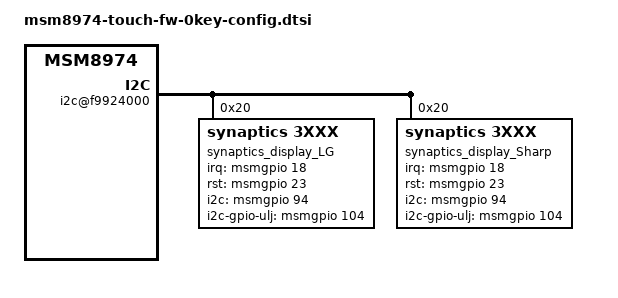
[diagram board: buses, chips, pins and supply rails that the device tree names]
/* Copyright (c) 2013, The Linux Foundation. All rights reserved.
 *
 * This program is free software; you can redistribute it and/or modify
 * it under the terms of the GNU General Public License version 2 and
 * only version 2 as published by the Free Software Foundation.
 *
 * This program is distributed in the hope that it will be useful,
 * but WITHOUT ANY WARRANTY; without even the implied warranty of
 * MERCHANTABILITY or FITNESS FOR A PARTICULAR PURPOSE.  See the
 * GNU General Public License for more details.
 */

&soc {
	i2c@f9924000 {
		synaptics_display_LG@20 {
			compatible               = "synaptics,3xxx";
			reg                      = <0x20>;
			interrupt-parent         = <&msmgpio>;
			interrupts               = <18 0x2>;
			synaptics,display-coords = <0 1080 0 1920>;
			synaptics,irq-gpio       = <&msmgpio 18 0x00>;
			synaptics,rst-gpio       = <&msmgpio 23 0x00>;
			synaptics,i2c-gpio       = <&msmgpio 94 0x00>;
			synaptics,i2c-gpio-ulj   = <&msmgpio 104 0x00>;
			synaptics,i2c_err_hlr    = <1>;
			tw_pin_mask              = <0x05>;
			hall_block_touch_time    = <1000>;
			report_type              = <1>;
			virtualkey0              = <&syn_vk>;
			virtualkey1              = <&syn_vk_1>;
			virtualkey2              = <&syn_vk_t6>;

			config_3528_0key_yfo_6 {
				default_cfg   = <1>;
				pr_number     = <1594356>;
				sensor_id     = <0x0>;
				syn,pl-coords = <0 1620 0 2880>;
				cover_setting = <0x0D 0x0D 0x1A 0x0A 0x82 0x82 0x06>;
				tp_stock_ui_check	 = <1>;
				config = [
					31 35 04 21 00 3F 03 14
					05 1D 54 06 40 0B 23 43
					5A 41 00 00 00 00 0F 1B
					01 1E 05 F5 28 1E 05 28
					10 03 12 02 CC C4 CC C4
					83 80 C4 C4 05 03 10 1E
					80 0F 0A 64 00 01 01 07
					04 04 0A C0 0A 64 26 26
					80 80 00 00 82 5F 48 64
					33 19 00 40 40 2D 50 00
					00 00 00 4C 04 6C 07 3C
					32 00 00 00 00 4C 04 6C
					07 1E 05 1E 04 0A 04 0A
					00 0A 04 04 01 01 00 00
					01 05 0A 01 00 00 06 39
					01 00 18 00 06 39 01 00
					18 33 33 CC 1C 02 19 10
					0A 64 06 64 06 C8 88 1F
					40 00 40 00 32 23 4B 50
					37 3C 0C 0C 00 00 14 14
					00 03 00 03 09 96 00 00
					14 03 06 0F 0A 00 4B FF
					00 0A C8 0A B4 64 B4 C8
					B4 C8 B4 C8 B4 C8 B4 C8
					00 05 DC 05 C8 32 C8 64
					C8 64 C8 64 C8 64 C8 64
					00 04 01 80 04 1B 00 00
					00 2C 01 FF FF BF 32 2C
					01 00 C0 80 00 10 0A 18
					00 7D 01 10 27 00 A0 00
					03 00 02 02 07 07 05 A0
					00 0C 0E 01 04 03 28 00
					10 00 00 00 07 00 02 25
					03 28 00 0F 00 02 00 07
					00 02 27 83 28 00 0F 00
					04 00 04 00 01 23 83 28
					00 0F 00 06 00 04 00 01
					24 03 28 00 0E 00 08 00
					04 00 01 25 83 28 00 0E
					00 0A 00 04 00 01 26 83
					28 00 0E 00 0C 00 09 00
					02 23 83 28 00 0D 00 0E
					00 09 00 02 24 0E 0E 0E
					0E 0E 0E 0E 0F 0F 0F 0F
					0F 0F 0F 0F 00 00 00 00
					00 00 00 03 03 03 03 03
					03 03 03 03 03 03 03 03
					03 03 03 03 03 03 03 03
					03 0E 0D 0D 0D 0D 0D 0D
					0D 0D 0D 0D 0D 0D 0D 0D
					0E 0D 0D 0D 0D 0D 0D 0D
					0D 0D 0D 0D 0D 0D 0D 0D
					0B 02 02 01 00 07 0B 0B
					03 00 05 34 00 06 00 A6
					00 14 64 05 00 00 02 02
					04 04 04 04 03 1B 28 05
					00 00 16 12 00 05 02 14
					A1 02 06 1E 08 A0 00 A0
					00 1E 03 0C 0C 14 28 04
					00 00 00 00 00 00 00 00
					00 00 00 20 00 00 00 FF
					FF FF FF FF FF FF FF 51
					51 51 51 CD 0D 04 83 10
					10 10 10 05 20 1F 1E 1D
					1C 1B 1A 18 17 16 15 14
					13 12 11 FF FF FF FF FF
					FF FF 00 01 02 03 04 05
					06 07 08 09 0A 0B 0C 0D
					33 32 31 30 2F 2E 2D 2C
					2B 2A 29 28 27 FF FF FF
					FF FF 00 10 00 10 00 10
					00 10 80 80 80 80 80 80
					80 80 80 80 80 80 80 80
					80 80 80 80 80 80 80 80
					80 80 80 80 80 80 80 80
					80 80 80 80 80 80 80 9A
					9A 80 80 80 80 80 80 80
					80 80 80 80 80 80 80 80
					00 10 00 10 00 10 00 10
					00 00 21 22 FF FF 0E 26
					35 FF
				];
			};

			config_3528_0key_pana_6 {
				default_cfg   = <1>;
				pr_number     = <1594356>;
				sensor_id     = <0x1>;
				syn,pl-coords = <0 1620 0 2880>;
				cover_setting = <0x0D 0x0D 0x1A 0x0A 0x82 0x82 0x06>;
				tp_stock_ui_check	 = <1>;
				config = [
					31 35 04 21 00 3F 03 14
					05 1D 54 06 40 0B 23 43
					5A 41 00 00 00 00 0F 1B
					01 1E 05 F5 28 1E 05 28
					10 03 12 02 CC C4 CC C4
					83 80 C4 C4 05 03 10 1E
					80 0F 0A 64 00 01 01 07
					04 04 0A C0 0A 64 26 26
					80 80 00 00 82 5F 48 64
					33 19 00 40 40 2D 50 00
					00 00 00 4C 04 6C 07 3C
					32 00 00 00 00 4C 04 6C
					07 1E 05 1E 04 0A 04 0A
					00 0A 04 04 01 01 00 00
					01 05 0A 01 00 00 06 39
					01 00 18 00 06 39 01 00
					18 33 33 CC 1C 02 19 10
					0A 64 06 64 06 C8 88 1F
					40 00 40 00 32 23 4B 50
					37 3C 0C 0C 00 00 14 14
					00 03 00 03 09 96 00 00
					14 03 06 0F 0A 00 4B FF
					00 0A C8 0A B4 64 B4 C8
					B4 C8 B4 C8 B4 C8 B4 C8
					00 05 DC 05 C8 32 C8 64
					C8 64 C8 64 C8 64 C8 64
					00 04 01 80 04 1B 00 00
					00 2C 01 FF FF BF 32 2C
					01 00 C0 80 00 10 0A 18
					00 7D 01 10 27 00 A0 00
					03 00 02 02 07 07 05 A0
					00 0C 0E 01 04 03 28 00
					10 00 00 00 07 00 02 25
					03 28 00 0F 00 02 00 07
					00 02 27 83 28 00 0F 00
					04 00 04 00 01 23 83 28
					00 0F 00 06 00 04 00 01
					24 03 28 00 0E 00 08 00
					04 00 01 25 83 28 00 0E
					00 0A 00 04 00 01 26 83
					28 00 0E 00 0C 00 09 00
					02 23 83 28 00 0D 00 0E
					00 09 00 02 24 0E 0E 0E
					0E 0E 0E 0E 0F 0F 0F 0F
					0F 0F 0F 0F 00 00 00 00
					00 00 00 03 03 03 03 03
					03 03 03 03 03 03 03 03
					03 03 03 03 03 03 03 03
					03 0E 0D 0D 0D 0D 0D 0D
					0D 0D 0D 0D 0D 0D 0D 0D
					0E 0D 0D 0D 0D 0D 0D 0D
					0D 0D 0D 0D 0D 0D 0D 0D
					0B 02 02 01 00 07 0B 0B
					03 00 05 34 00 06 00 A6
					00 14 64 05 00 00 02 02
					04 04 04 04 03 1B 28 05
					00 00 16 12 00 05 02 14
					A1 02 06 1E 08 A0 00 A0
					00 1E 03 0C 0C 14 28 04
					00 00 00 00 00 00 00 00
					00 00 00 20 00 00 00 FF
					FF FF FF FF FF FF FF 51
					51 51 51 CD 0D 04 83 10
					10 10 10 05 20 1F 1E 1D
					1C 1B 1A 18 17 16 15 14
					13 12 11 FF FF FF FF FF
					FF FF 00 01 02 03 04 05
					06 07 08 09 0A 0B 0C 0D
					33 32 31 30 2F 2E 2D 2C
					2B 2A 29 28 27 FF FF FF
					FF FF 00 10 00 10 00 10
					00 10 80 80 80 80 80 80
					80 80 80 80 80 80 80 80
					80 80 80 80 80 80 80 80
					80 80 80 80 80 80 80 80
					80 80 80 80 80 80 80 9A
					9A 80 80 80 80 80 80 80
					80 80 80 80 80 80 80 80
					00 10 00 10 00 10 00 10
					00 00 21 22 FF FF 0E 26
					35 FF
				];
			};

			config_3528_0key_yfo_5 {
				default_cfg   = <1>;
				pr_number     = <1594356>;
				sensor_id     = <0x0>;
				syn,pl-coords = <0 1620 0 2880>;
				cover_setting = <0x0D 0x0D 0x1A 0x0A 0x82 0x82 0x06>;
				config = [
					31 35 04 22 00 3F 03 14
					05 1D 54 06 40 0B 23 43
					5A 41 00 00 00 00 0F 1B
					01 1E 05 F5 28 1E 05 28
					10 03 12 02 CC C4 CC C4
					83 80 C4 C4 05 03 10 16
					80 0F 0A 64 00 01 01 07
					04 04 0A C0 0A 64 26 26
					80 80 00 00 82 5F 48 64
					2E 19 00 40 40 2D 50 00
					00 00 00 4C 04 6C 07 3C
					32 00 00 00 00 4C 04 6C
					07 1E 05 1E 04 0A 04 0A
					00 0A 04 04 01 01 00 00
					01 05 0A 01 00 00 06 39
					01 00 18 00 06 39 01 00
					18 33 33 CC 1C 02 19 10
					0A 64 06 64 06 C8 88 1F
					40 00 40 00 32 23 4B 50
					37 3C 0C 0C 00 00 14 14
					00 03 00 03 09 96 00 00
					14 03 06 0F 0A 00 4B FF
					00 0A C8 0A B4 64 B4 C8
					B4 C8 B4 C8 B4 C8 B4 C8
					00 05 DC 05 C8 32 C8 64
					C8 64 C8 64 C8 64 C8 64
					00 04 01 80 04 1B 00 00
					00 2C 01 FF FF BF 32 2C
					01 00 C0 80 00 10 0A 18
					00 7D 01 10 27 00 A0 00
					03 00 02 02 07 07 05 A0
					00 0C 0E 01 04 03 28 00
					10 00 00 00 07 00 02 25
					03 28 00 0F 00 02 00 07
					00 02 27 83 28 00 0F 00
					04 00 04 00 01 23 83 28
					00 0F 00 06 00 04 00 01
					24 03 28 00 0E 00 08 00
					04 00 01 25 83 28 00 0E
					00 0A 00 04 00 01 26 83
					28 00 0E 00 0C 00 09 00
					02 23 83 28 00 0D 00 0E
					00 09 00 02 24 0E 0E 0E
					0E 0E 0E 0E 0F 0F 0F 0F
					0F 0F 0F 0F 00 00 00 00
					00 00 00 03 03 03 03 03
					03 03 03 03 03 03 03 03
					03 03 03 03 03 03 03 03
					03 0E 0D 0D 0D 0D 0D 0D
					0D 0D 0D 0D 0D 0D 0D 0D
					0E 0D 0D 0D 0D 0D 0D 0D
					0D 0D 0D 0D 0D 0D 0D 0D
					0B 02 02 01 00 07 0B 0B
					03 00 05 34 00 06 00 A6
					00 14 64 05 00 00 02 02
					04 04 04 04 03 1B 28 05
					00 00 16 12 00 05 02 14
					A1 02 06 1E 08 A0 00 A0
					00 1E 03 0C 0C 14 28 04
					00 00 00 00 00 00 00 00
					00 00 00 20 00 00 00 FF
					FF FF FF FF FF FF FF 51
					51 51 51 CD 0D 04 83 10
					10 10 10 05 20 1F 1E 1D
					1C 1B 1A 18 17 16 15 14
					13 12 11 FF FF FF FF FF
					FF FF 00 01 02 03 04 05
					06 07 08 09 0A 0B 0C 0D
					33 32 31 30 2F 2E 2D 2C
					2B 2A 29 28 27 FF FF FF
					FF FF 00 10 00 10 00 10
					00 10 80 80 80 80 80 80
					80 80 80 80 80 80 80 80
					80 80 80 80 80 80 80 80
					80 80 80 80 80 80 80 80
					80 80 80 80 80 80 80 9A
					9A 80 80 80 80 80 80 80
					80 80 80 80 80 80 80 80
					00 10 00 10 00 10 00 10
					00 00 21 22 FF FF 0E 26
					35 FF
				];
			};

			config_3528_0key_pana_5 {
				default_cfg   = <1>;
				pr_number     = <1594356>;
				sensor_id     = <0x1>;
				syn,pl-coords = <0 1620 0 2880>;
				cover_setting = <0x0D 0x0D 0x1A 0x0A 0x82 0x82 0x06>;
				config = [
					31 35 04 22 00 3F 03 14
					05 1D 54 06 40 0B 23 43
					5A 41 00 00 00 00 0F 1B
					01 1E 05 F5 28 1E 05 28
					10 03 12 02 CC C4 CC C4
					83 80 C4 C4 05 03 10 16
					80 0F 0A 64 00 01 01 07
					04 04 0A C0 0A 64 26 26
					80 80 00 00 82 5F 48 64
					2E 19 00 40 40 2D 50 00
					00 00 00 4C 04 6C 07 3C
					32 00 00 00 00 4C 04 6C
					07 1E 05 1E 04 0A 04 0A
					00 0A 04 04 01 01 00 00
					01 05 0A 01 00 00 06 39
					01 00 18 00 06 39 01 00
					18 33 33 CC 1C 02 19 10
					0A 64 06 64 06 C8 88 1F
					40 00 40 00 32 23 4B 50
					37 3C 0C 0C 00 00 14 14
					00 03 00 03 09 96 00 00
					14 03 06 0F 0A 00 4B FF
					00 0A C8 0A B4 64 B4 C8
					B4 C8 B4 C8 B4 C8 B4 C8
					00 05 DC 05 C8 32 C8 64
					C8 64 C8 64 C8 64 C8 64
					00 04 01 80 04 1B 00 00
					00 2C 01 FF FF BF 32 2C
					01 00 C0 80 00 10 0A 18
					00 7D 01 10 27 00 A0 00
					03 00 02 02 07 07 05 A0
					00 0C 0E 01 04 03 28 00
					10 00 00 00 07 00 02 25
					03 28 00 0F 00 02 00 07
					00 02 27 83 28 00 0F 00
					04 00 04 00 01 23 83 28
					00 0F 00 06 00 04 00 01
					24 03 28 00 0E 00 08 00
					04 00 01 25 83 28 00 0E
					00 0A 00 04 00 01 26 83
					28 00 0E 00 0C 00 09 00
					02 23 83 28 00 0D 00 0E
					00 09 00 02 24 0E 0E 0E
					0E 0E 0E 0E 0F 0F 0F 0F
					0F 0F 0F 0F 00 00 00 00
					00 00 00 03 03 03 03 03
					03 03 03 03 03 03 03 03
					03 03 03 03 03 03 03 03
					03 0E 0D 0D 0D 0D 0D 0D
					0D 0D 0D 0D 0D 0D 0D 0D
					0E 0D 0D 0D 0D 0D 0D 0D
					0D 0D 0D 0D 0D 0D 0D 0D
					0B 02 02 01 00 07 0B 0B
					03 00 05 34 00 06 00 A6
					00 14 64 05 00 00 02 02
					04 04 04 04 03 1B 28 05
					00 00 16 12 00 05 02 14
					A1 02 06 1E 08 A0 00 A0
					00 1E 03 0C 0C 14 28 04
					00 00 00 00 00 00 00 00
					00 00 00 20 00 00 00 FF
					FF FF FF FF FF FF FF 51
					51 51 51 CD 0D 04 83 10
					10 10 10 05 20 1F 1E 1D
					1C 1B 1A 18 17 16 15 14
					13 12 11 FF FF FF FF FF
					FF FF 00 01 02 03 04 05
					06 07 08 09 0A 0B 0C 0D
					33 32 31 30 2F 2E 2D 2C
					2B 2A 29 28 27 FF FF FF
					FF FF 00 10 00 10 00 10
					00 10 80 80 80 80 80 80
					80 80 80 80 80 80 80 80
					80 80 80 80 80 80 80 80
					80 80 80 80 80 80 80 80
					80 80 80 80 80 80 80 9A
					9A 80 80 80 80 80 80 80
					80 80 80 80 80 80 80 80
					00 10 00 10 00 10 00 10
					00 00 21 22 FF FF 0E 26
					35 FF
				];
			};

			config_3528_0key_yfo_4 {
				default_cfg   = <1>;
				pr_number     = <1589401>;
				sensor_id     = <0x0>;
				syn,pl-coords = <0 1620 0 2880>;
				cover_setting = <0x0D 0x0D 0x1A 0x0A 0x82 0x82 0x06>;
				config = [
					31 35 04 14 00 3F 03 1E
					05 1D 54 06 40 0B 23 43
					5A 41 00 00 00 00 0F 1B
					01 1E 05 F5 28 1E 05 28
					10 03 12 02 CC C4 CC C4
					83 80 C4 C4 05 03 10 16
					80 0F 0A 64 00 01 01 07
					04 04 0A C0 0A 64 26 26
					80 80 00 00 82 5F 48 64
					2E 23 00 40 40 2D 50 00
					00 00 00 4C 04 6C 07 3C
					32 00 00 00 00 4C 04 6C
					07 1E 05 1E 04 0A 04 0A
					00 0A 04 04 01 01 00 00
					01 05 0A 01 00 00 06 39
					01 00 18 00 06 39 01 00
					18 33 33 CC 1C 02 19 10
					0A 64 06 64 06 C8 88 1F
					40 00 40 00 32 23 4B 50
					37 3C 0C 0C 00 00 14 14
					00 03 00 03 09 96 00 00
					14 03 06 0F 0A 00 4B FF
					00 0A C8 0A B4 64 B4 C8
					B4 C8 B4 C8 B4 C8 B4 C8
					00 05 DC 05 C8 32 C8 64
					C8 64 C8 64 C8 64 C8 64
					00 04 01 80 04 1B 00 00
					00 82 00 FF FF BF 32 2C
					01 00 C0 80 00 10 0A 18
					00 7D 01 04 00 00 A0 00
					03 00 02 02 07 07 05 A0
					00 0C 0E 02 04 00 1A 00
					10 00 00 00 07 00 02 25
					00 19 00 0F 00 02 00 07
					00 02 27 80 18 00 0F 00
					05 00 04 00 01 24 80 17
					00 0E 00 08 00 04 00 01
					25 00 16 00 0E 00 0B 00
					09 00 02 22 80 16 00 0D
					00 0E 00 09 00 02 24 80
					15 00 0D 00 11 00 09 00
					02 25 80 14 00 0C 00 15
					00 05 00 01 23 0E 0E 0E
					0E 0E 0E 0E 0F 0F 0F 0F
					0F 0F 0F 0F 00 00 00 00
					00 00 00 03 03 03 03 03
					03 03 03 03 03 03 03 03
					03 03 03 03 03 03 03 03
					03 0E 0D 0D 0D 0D 0D 0D
					0D 0D 0D 0D 0D 0D 0D 0D
					0E 0D 0D 0D 0D 0D 0D 0D
					0D 0D 0D 0D 0D 0D 0D 0D
					0B 02 02 01 00 07 0B 0B
					03 00 05 34 00 06 00 A6
					00 14 64 05 00 00 02 02
					04 04 04 04 03 1B 28 05
					00 00 14 12 00 05 02 16
					A1 02 06 1E 08 A0 00 A0
					00 1E 03 0C 0C 14 28 04
					00 00 00 00 00 00 00 00
					00 00 00 20 00 00 00 FF
					FF FF FF FF FF FF FF 51
					51 51 51 CD 0D 04 83 10
					10 10 10 05 20 1F 1E 1D
					1C 1B 1A 18 17 16 15 14
					13 12 11 FF FF FF FF FF
					FF FF 00 01 02 03 04 05
					06 07 08 09 0A 0B 0C 0D
					33 32 31 30 2F 2E 2D 2C
					2B 2A 29 28 27 FF FF FF
					FF FF 00 10 00 10 00 10
					00 10 80 80 80 80 80 80
					80 80 80 80 80 80 80 80
					80 80 80 80 80 80 80 80
					80 80 80 80 80 80 80 80
					80 80 80 80 80 80 80 80
					80 80 80 80 80 80 80 80
					80 80 80 80 80 80 80 80
					00 10 00 10 00 10 00 10
					00 00 21 22 FF FF 0E 26
					35 FF
				];
			};

			config_3528_0key_pana_4 {
				default_cfg   = <1>;
				pr_number     = <1589401>;
				sensor_id     = <0x1>;
				syn,pl-coords = <0 1620 0 2880>;
				cover_setting = <0x0D 0x0D 0x1A 0x0A 0x82 0x82 0x06>;
				config = [
					31 35 04 14 00 3F 03 1E
					05 1D 54 06 40 0B 23 43
					5A 41 00 00 00 00 0F 1B
					01 1E 05 F5 28 1E 05 28
					10 03 12 02 CC C4 CC C4
					83 80 C4 C4 05 03 10 16
					80 0F 0A 64 00 01 01 07
					04 04 0A C0 0A 64 26 26
					80 80 00 00 82 5F 48 64
					2E 23 00 40 40 2D 50 00
					00 00 00 4C 04 6C 07 3C
					32 00 00 00 00 4C 04 6C
					07 1E 05 1E 04 0A 04 0A
					00 0A 04 04 01 01 00 00
					01 05 0A 01 00 00 06 39
					01 00 18 00 06 39 01 00
					18 33 33 CC 1C 02 19 10
					0A 64 06 64 06 C8 88 1F
					40 00 40 00 32 23 4B 50
					37 3C 0C 0C 00 00 14 14
					00 03 00 03 09 96 00 00
					14 03 06 0F 0A 00 4B FF
					00 0A C8 0A B4 64 B4 C8
					B4 C8 B4 C8 B4 C8 B4 C8
					00 05 DC 05 C8 32 C8 64
					C8 64 C8 64 C8 64 C8 64
					00 04 01 80 04 1B 00 00
					00 82 00 FF FF BF 32 2C
					01 00 C0 80 00 10 0A 18
					00 7D 01 04 00 00 A0 00
					03 00 02 02 07 07 05 A0
					00 0C 0E 02 04 00 1A 00
					10 00 00 00 07 00 02 25
					00 19 00 0F 00 02 00 07
					00 02 27 80 18 00 0F 00
					05 00 04 00 01 24 80 17
					00 0E 00 08 00 04 00 01
					25 00 16 00 0E 00 0B 00
					09 00 02 22 80 16 00 0D
					00 0E 00 09 00 02 24 80
					15 00 0D 00 11 00 09 00
					02 25 80 14 00 0C 00 15
					00 05 00 01 23 0E 0E 0E
					0E 0E 0E 0E 0F 0F 0F 0F
					0F 0F 0F 0F 00 00 00 00
					00 00 00 03 03 03 03 03
					03 03 03 03 03 03 03 03
					03 03 03 03 03 03 03 03
					03 0E 0D 0D 0D 0D 0D 0D
					0D 0D 0D 0D 0D 0D 0D 0D
					0E 0D 0D 0D 0D 0D 0D 0D
					0D 0D 0D 0D 0D 0D 0D 0D
					0B 02 02 01 00 07 0B 0B
					03 00 05 34 00 06 00 A6
					00 14 64 05 00 00 02 02
					04 04 04 04 03 1B 28 05
					00 00 14 12 00 05 02 16
					A1 02 06 1E 08 A0 00 A0
					00 1E 03 0C 0C 14 28 04
					00 00 00 00 00 00 00 00
					00 00 00 20 00 00 00 FF
					FF FF FF FF FF FF FF 51
					51 51 51 CD 0D 04 83 10
					10 10 10 05 20 1F 1E 1D
					1C 1B 1A 18 17 16 15 14
					13 12 11 FF FF FF FF FF
					FF FF 00 01 02 03 04 05
					06 07 08 09 0A 0B 0C 0D
					33 32 31 30 2F 2E 2D 2C
					2B 2A 29 28 27 FF FF FF
					FF FF 00 10 00 10 00 10
					00 10 80 80 80 80 80 80
					80 80 80 80 80 80 80 80
					80 80 80 80 80 80 80 80
					80 80 80 80 80 80 80 80
					80 80 80 80 80 80 80 80
					80 80 80 80 80 80 80 80
					80 80 80 80 80 80 80 80
					00 10 00 10 00 10 00 10
					00 00 21 22 FF FF 0E 26
					35 FF
				];
			};

			config_3528_0key_yfo_3 {
				default_cfg   = <1>;
				pr_number     = <1584735>;
				sensor_id     = <0x0>;
				syn,pl-coords = <0 1620 0 2880>;
				config = [
					31 35 04 11 00 3F 03 1E
					05 1D 54 06 40 0B 23 43
					5A 41 00 00 00 00 0F 1B
					01 1E 05 F5 28 1E 05 28
					10 03 12 02 CC C4 CC C4
					83 80 C4 C4 05 03 1C 1E
					80 0F 0A 64 00 01 01 07
					04 04 0A C0 0A 64 26 26
					80 80 00 00 C0 53 5B 80
					2E 1A 00 40 40 2D 50 00
					00 00 00 4C 04 6C 07 3C
					32 00 00 00 00 4C 04 6C
					07 1E 05 1E 04 0A 04 0A
					00 0A 04 04 01 01 00 00
					01 05 0A 0A 00 00 06 39
					01 00 18 00 06 39 01 00
					18 33 33 CC 1C 02 19 10
					0A 64 06 64 06 C8 88 1F
					40 00 40 00 32 23 4B 50
					37 3C 0C 0C 00 00 14 14
					00 03 00 03 09 96 00 00
					14 03 06 0F 0A 00 4B FF
					FF 19 FF 19 FF 19 FF 19
					FF 19 FF 19 FF 19 FF 19
					FF 13 FF 13 FF 13 FF 13
					FF 13 FF 13 FF 13 FF 13
					00 04 01 80 04 1B 00 00
					00 64 00 F4 01 BF 28 F4
					01 00 C0 80 00 10 0A 18
					00 7D 01 03 00 00 64 00
					03 00 06 06 07 07 00 64
					00 0C 0E 01 04 00 1A 00
					10 00 00 00 07 00 02 25
					00 19 00 0F 00 02 00 07
					00 02 27 80 18 00 0F 00
					05 00 04 00 01 24 80 17
					00 0E 00 08 00 04 00 01
					25 80 16 00 0E 00 0B 00
					09 00 02 22 00 16 00 0D
					00 0E 00 09 00 02 24 80
					15 00 0D 00 11 00 09 00
					02 25 80 14 00 0C 00 15
					00 05 00 01 23 00 00 00
					00 00 00 00 00 00 00 00
					00 00 00 00 00 00 00 00
					00 00 00 03 03 03 03 03
					03 03 03 03 03 03 03 03
					03 03 03 03 03 03 03 03
					03 0E 0D 0D 0D 0D 0D 0D
					0D 0D 0D 0D 0D 0D 0D 0D
					0E 0D 0D 0D 0D 0D 0D 0D
					0D 0D 0D 0D 0D 0D 0D 0D
					0B 02 02 01 00 07 0B 0B
					03 00 05 34 00 06 00 A6
					00 14 64 05 00 00 02 02
					04 04 04 04 03 1B 28 05
					00 00 16 12 00 05 02 16
					A1 02 06 1E 08 A0 00 A0
					00 1E 03 0C 0C 14 28 04
					00 00 00 00 00 00 00 00
					00 00 00 20 00 00 00 FF
					FF FF FF FF FF FF FF 51
					51 51 51 CD 0D 04 83 10
					10 10 10 05 20 1F 1E 1D
					1C 1B 1A 18 17 16 15 14
					13 12 11 FF FF FF FF FF
					FF FF 00 01 02 03 04 05
					06 07 08 09 0A 0B 0C 0D
					33 32 31 30 2F 2E 2D 2C
					2B 2A 29 28 27 FF FF FF
					FF FF 00 10 00 10 00 10
					00 10 80 80 80 80 80 80
					80 80 80 80 80 80 80 80
					80 80 80 80 80 80 80 80
					80 80 80 80 80 80 80 80
					80 80 80 80 80 80 80 80
					80 80 80 80 80 80 80 80
					80 80 80 80 80 80 80 80
					00 10 00 10 00 10 00 10
					00 00 21 22 FF FF 0E 26
					35 FF
				];
			};

			config_3528_0key_pana_3 {
				default_cfg   = <1>;
				pr_number     = <1584735>;
				sensor_id     = <0x1>;
				syn,pl-coords = <0 1620 0 2880>;
				config = [
					31 35 04 11 00 3F 03 1E
					05 1D 54 06 40 0B 23 43
					5A 41 00 00 00 00 0F 1B
					01 1E 05 F5 28 1E 05 28
					10 03 12 02 CC C4 CC C4
					83 80 C4 C4 05 03 1C 1E
					80 0F 0A 64 00 01 01 07
					04 04 0A C0 0A 64 26 26
					80 80 00 00 C0 53 5B 80
					2E 1A 00 40 40 2D 50 00
					00 00 00 4C 04 6C 07 3C
					32 00 00 00 00 4C 04 6C
					07 1E 05 1E 04 0A 04 0A
					00 0A 04 04 01 01 00 00
					01 05 0A 0A 00 00 06 39
					01 00 18 00 06 39 01 00
					18 33 33 CC 1C 02 19 10
					0A 64 06 64 06 C8 88 1F
					40 00 40 00 32 23 4B 50
					37 3C 0C 0C 00 00 14 14
					00 03 00 03 09 96 00 00
					14 03 06 0F 0A 00 4B FF
					FF 19 FF 19 FF 19 FF 19
					FF 19 FF 19 FF 19 FF 19
					FF 13 FF 13 FF 13 FF 13
					FF 13 FF 13 FF 13 FF 13
					00 04 01 80 04 1B 00 00
					00 64 00 F4 01 BF 28 F4
					01 00 C0 80 00 10 0A 18
					00 7D 01 03 00 00 64 00
					03 00 06 06 07 07 00 64
					00 0C 0E 01 04 00 1A 00
					10 00 00 00 07 00 02 25
					00 19 00 0F 00 02 00 07
					00 02 27 80 18 00 0F 00
					05 00 04 00 01 24 80 17
					00 0E 00 08 00 04 00 01
					25 80 16 00 0E 00 0B 00
					09 00 02 22 00 16 00 0D
					00 0E 00 09 00 02 24 80
					15 00 0D 00 11 00 09 00
					02 25 80 14 00 0C 00 15
					00 05 00 01 23 00 00 00
					00 00 00 00 00 00 00 00
					00 00 00 00 00 00 00 00
					00 00 00 03 03 03 03 03
					03 03 03 03 03 03 03 03
					03 03 03 03 03 03 03 03
					03 0E 0D 0D 0D 0D 0D 0D
					0D 0D 0D 0D 0D 0D 0D 0D
					0E 0D 0D 0D 0D 0D 0D 0D
					0D 0D 0D 0D 0D 0D 0D 0D
					0B 02 02 01 00 07 0B 0B
					03 00 05 34 00 06 00 A6
					00 14 64 05 00 00 02 02
					04 04 04 04 03 1B 28 05
					00 00 16 12 00 05 02 16
					A1 02 06 1E 08 A0 00 A0
					00 1E 03 0C 0C 14 28 04
					00 00 00 00 00 00 00 00
					00 00 00 20 00 00 00 FF
					FF FF FF FF FF FF FF 51
					51 51 51 CD 0D 04 83 10
					10 10 10 05 20 1F 1E 1D
					1C 1B 1A 18 17 16 15 14
					13 12 11 FF FF FF FF FF
					FF FF 00 01 02 03 04 05
					06 07 08 09 0A 0B 0C 0D
					33 32 31 30 2F 2E 2D 2C
					2B 2A 29 28 27 FF FF FF
					FF FF 00 10 00 10 00 10
					00 10 80 80 80 80 80 80
					80 80 80 80 80 80 80 80
					80 80 80 80 80 80 80 80
					80 80 80 80 80 80 80 80
					80 80 80 80 80 80 80 80
					80 80 80 80 80 80 80 80
					80 80 80 80 80 80 80 80
					00 10 00 10 00 10 00 10
					00 00 21 22 FF FF 0E 26
					35 FF
				];
			};

			config_3528_0key_yfo_2 {
				default_cfg   = <1>;
				pr_number     = <1582731>;
				sensor_id     = <0x0>;
				syn,pl-coords = <0 1620 0 2880>;
				config = [
					31 35 04 09 00 3F 03 1E
					05 1D 54 06 40 0B 23 43
					5A 41 00 00 00 00 0F 1B
					01 1E 05 F5 28 1E 05 28
					10 03 12 02 CC C4 CC C4
					83 80 C4 C4 05 03 0C 12
					80 0F 0A 64 00 01 01 07
					04 04 0A C0 0A 64 26 26
					80 80 00 00 C0 53 5B 80
					26 0E 00 40 40 2D 50 00
					00 00 00 4C 04 6C 07 3C
					32 00 00 00 00 4C 04 6C
					07 1E 05 1E 04 0A 04 0A
					00 0A 04 04 01 01 00 00
					15 05 0A 0A 00 00 06 39
					01 00 18 00 06 39 01 00
					18 33 33 CC 1C 02 19 10
					0A 64 06 64 06 C8 88 1F
					40 00 40 00 32 23 4B 50
					37 3C 0C 0C 00 00 14 14
					00 03 00 03 09 96 00 00
					14 03 06 0F 0A 00 4B FF
					00 19 80 19 C0 80 C0 FF
					00 19 00 19 00 19 00 19
					00 13 C0 13 FF 80 FF FF
					FF FF FF FF FF FF FF FF
					00 04 01 80 04 1B 00 00
					00 64 00 F4 01 BF 28 F4
					01 00 C0 80 00 10 0A 18
					00 7D 01 03 00 00 96 00
					03 00 06 06 07 07 00 96
					00 0C 0E 01 04 00 1A 00
					10 00 00 00 07 00 02 25
					00 19 00 0F 00 02 00 07
					00 02 27 80 18 00 0F 00
					05 00 04 00 01 24 80 17
					00 0E 00 08 00 04 00 01
					25 00 16 00 0E 00 0B 00
					09 00 02 22 80 16 00 0D
					00 0E 00 09 00 02 24 80
					15 00 0D 00 11 00 09 00
					02 25 80 14 00 0C 00 15
					00 05 00 01 23 00 00 00
					00 00 00 00 00 00 00 00
					00 00 00 00 00 00 00 00
					00 00 00 03 03 03 03 03
					03 03 03 03 03 03 03 03
					03 03 03 03 03 03 03 03
					03 0E 0D 0D 0D 0D 0D 0D
					0D 0D 0D 0D 0D 0D 0D 0D
					0E 0D 0D 0D 0D 0D 0D 0D
					0D 0D 0D 0D 0D 0D 0D 0D
					0B 02 02 01 00 07 0B 0B
					03 00 05 34 00 06 00 A6
					00 14 64 05 00 00 02 02
					04 04 04 04 03 1B 28 05
					00 00 16 12 00 05 02 14
					A1 02 06 1E 08 A0 00 A0
					00 1E 03 0C 0C 14 28 04
					00 00 00 00 00 00 00 00
					00 00 00 20 00 00 00 FF
					FF FF FF FF FF FF FF 51
					51 51 51 CD 0D 04 83 10
					10 10 10 05 20 1F 1E 1D
					1C 1B 1A 18 17 16 15 14
					13 12 11 FF FF FF FF FF
					FF FF 00 01 02 03 04 05
					06 07 08 09 0A 0B 0C 0D
					33 32 31 30 2F 2E 2D 2C
					2B 2A 29 28 27 FF FF FF
					FF FF 00 10 00 10 00 10
					00 10 80 80 80 80 80 80
					80 80 80 80 80 80 80 80
					80 80 80 80 80 80 80 80
					80 80 80 80 80 80 80 80
					80 80 80 80 80 80 80 80
					80 80 80 80 80 80 80 80
					80 80 80 80 80 80 80 80
					00 10 00 10 00 10 00 10
					00 00 21 22 FF FF 0E 26
					35 FF
				];
			};

			config_3528_0key_pana_2 {
				default_cfg   = <1>;
				pr_number     = <1582731>;
				sensor_id     = <0x1>;
				syn,pl-coords = <0 1620 0 2880>;
				config = [
					31 35 04 09 00 3F 03 1E
					05 1D 54 06 40 0B 23 43
					5A 41 00 00 00 00 0F 1B
					01 1E 05 F5 28 1E 05 28
					10 03 12 02 CC C4 CC C4
					83 80 C4 C4 05 03 0C 12
					80 0F 0A 64 00 01 01 07
					04 04 0A C0 0A 64 26 26
					80 80 00 00 C0 53 5B 80
					26 0E 00 40 40 2D 50 00
					00 00 00 4C 04 6C 07 3C
					32 00 00 00 00 4C 04 6C
					07 1E 05 1E 04 0A 04 0A
					00 0A 04 04 01 01 00 00
					15 05 0A 0A 00 00 06 39
					01 00 18 00 06 39 01 00
					18 33 33 CC 1C 02 19 10
					0A 64 06 64 06 C8 88 1F
					40 00 40 00 32 23 4B 50
					37 3C 0C 0C 00 00 14 14
					00 03 00 03 09 96 00 00
					14 03 06 0F 0A 00 4B FF
					00 19 80 19 C0 80 C0 FF
					00 19 00 19 00 19 00 19
					00 13 C0 13 FF 80 FF FF
					FF FF FF FF FF FF FF FF
					00 04 01 80 04 1B 00 00
					00 64 00 F4 01 BF 28 F4
					01 00 C0 80 00 10 0A 18
					00 7D 01 03 00 00 96 00
					03 00 06 06 07 07 00 96
					00 0C 0E 01 04 00 1A 00
					10 00 00 00 07 00 02 25
					00 19 00 0F 00 02 00 07
					00 02 27 80 18 00 0F 00
					05 00 04 00 01 24 80 17
					00 0E 00 08 00 04 00 01
					25 00 16 00 0E 00 0B 00
					09 00 02 22 80 16 00 0D
					00 0E 00 09 00 02 24 80
					15 00 0D 00 11 00 09 00
					02 25 80 14 00 0C 00 15
					00 05 00 01 23 00 00 00
					00 00 00 00 00 00 00 00
					00 00 00 00 00 00 00 00
					00 00 00 03 03 03 03 03
					03 03 03 03 03 03 03 03
					03 03 03 03 03 03 03 03
					03 0E 0D 0D 0D 0D 0D 0D
					0D 0D 0D 0D 0D 0D 0D 0D
					0E 0D 0D 0D 0D 0D 0D 0D
					0D 0D 0D 0D 0D 0D 0D 0D
					0B 02 02 01 00 07 0B 0B
					03 00 05 34 00 06 00 A6
					00 14 64 05 00 00 02 02
					04 04 04 04 03 1B 28 05
					00 00 16 12 00 05 02 14
					A1 02 06 1E 08 A0 00 A0
					00 1E 03 0C 0C 14 28 04
					00 00 00 00 00 00 00 00
					00 00 00 20 00 00 00 FF
					FF FF FF FF FF FF FF 51
					51 51 51 CD 0D 04 83 10
					10 10 10 05 20 1F 1E 1D
					1C 1B 1A 18 17 16 15 14
					13 12 11 FF FF FF FF FF
					FF FF 00 01 02 03 04 05
					06 07 08 09 0A 0B 0C 0D
					33 32 31 30 2F 2E 2D 2C
					2B 2A 29 28 27 FF FF FF
					FF FF 00 10 00 10 00 10
					00 10 80 80 80 80 80 80
					80 80 80 80 80 80 80 80
					80 80 80 80 80 80 80 80
					80 80 80 80 80 80 80 80
					80 80 80 80 80 80 80 80
					80 80 80 80 80 80 80 80
					80 80 80 80 80 80 80 80
					00 10 00 10 00 10 00 10
					00 00 21 22 FF FF 0E 26
					35 FF
				];
			};

			config_3528_0key_yfo_1 {
				default_cfg   = <1>;
				pr_number     = <1564828>;
				sensor_id     = <0x0>;
				syn,pl-coords = <0 1620 0 2880>;
				config = [
					31 35 04 03 00 3F 03 05
					14 1D 54 06 40 0B 23 43
					5A 41 00 00 00 00 0F 1B
					01 1E 05 CD 2C A9 01 50
					16 02 1B 01 17 C3 59 E1
					83 80 C4 C4 05 03 0C 12
					80 0F 0A 64 00 01 01 07
					04 04 0A C0 0A 64 26 26
					80 80 00 00 4D 3B 01 40
					40 2D 50 00 00 00 00 4C
					04 6C 07 3C 32 00 00 00
					00 4C 04 6C 07 1E 05 1E
					04 0A 04 0A 00 0A 04 04
					01 01 00 00 01 15 0A 00
					00 00 04 39 01 00 18 F4
					01 39 01 00 18 33 33 CC
					1C 02 19 10 0A 30 06 30
					06 0A 88 1F 40 00 40 00
					32 23 4B 50 37 3C 0C 0C
					00 00 14 14 00 03 00 03
					09 96 00 00 14 03 06 0F
					0A 00 4B FF 00 04 01 80
					04 1B 00 00 00 C8 00 F4
					01 BF 32 F4 01 00 C0 80
					00 10 0A 18 00 7D 01 04
					00 00 96 00 03 00 06 06
					07 07 00 C8 00 0D 0D 01
					04 02 25 00 10 00 00 00
					07 00 02 24 02 23 00 10
					00 03 00 07 00 02 26 02
					22 00 0F 00 06 00 04 00
					01 23 81 20 00 0E 00 09
					00 04 00 01 24 01 1E 00
					0E 00 0E 00 09 00 02 23
					81 1C 00 0D 00 13 00 09
					00 02 25 80 1B 00 0C 00
					18 00 05 00 01 23 00 19
					00 0B 00 1F 00 05 00 01
					26 00 00 00 00 00 00 00
					00 00 00 00 00 00 00 00
					09 0F 00 00 00 00 00 03
					03 03 03 03 03 03 03 03
					03 03 03 03 03 03 03 03
					03 03 03 03 03 0E 0D 0D
					0D 0D 0D 0D 0D 0D 0D 0D
					0D 0D 0D 0D 0E 0D 0D 0D
					0D 0D 0D 0D 0D 0D 0D 0D
					0D 0D 0D 0D 0B 02 02 01
					00 06 0B 0B 03 00 05 32
					00 06 00 A6 00 14 64 05
					02 02 02 02 04 04 04 04
					00 2F 05 05 00 3F 38 00
					05 02 18 21 02 06 1E 08
					A0 00 A0 00 1E 03 0C 0C
					0A 0A 04 00 00 00 00 00
					00 00 00 00 00 00 00 00
					00 FF FF FF FF FF FF FF
					FF BF 97 51 51 CD 0D 04
					83 10 10 10 10 05 20 1F
					1E 1D 1C 1B 1A 18 17 16
					15 14 13 12 11 FF FF FF
					FF FF FF FF 00 01 02 03
					04 05 06 07 08 09 0A 0B
					0C 0D 33 32 31 30 2F 2E
					2D 2C 2B 2A 29 28 27 FF
					FF FF FF FF 00 10 00 10
					00 10 00 10 80 80 80 80
					80 80 80 80 80 80 80 80
					80 80 80 80 80 80 80 80
					80 80 80 80 80 80 80 80
					80 80 80 80 80 80 80 80
					80 80 80 80 80 80 80 80
					80 80 80 80 80 80 80 80
					80 80 00 10 00 10 00 10
					00 10 00 00 21 22 FF FF
					0E 26 35 FF
				];
			};

			config_3528_0key_pana_1 {
				default_cfg   = <1>;
				pr_number     = <1564828>;
				sensor_id     = <0x1>;
				syn,pl-coords = <0 1620 0 2880>;
				config = [
					31 35 04 03 00 3F 03 05
					14 1D 54 06 40 0B 23 43
					5A 41 00 00 00 00 0F 1B
					01 1E 05 CD 2C A9 01 50
					16 02 1B 01 17 C3 59 E1
					83 80 C4 C4 05 03 0C 12
					80 0F 0A 64 00 01 01 07
					04 04 0A C0 0A 64 26 26
					80 80 00 00 4D 3B 01 40
					40 2D 50 00 00 00 00 4C
					04 6C 07 3C 32 00 00 00
					00 4C 04 6C 07 1E 05 1E
					04 0A 04 0A 00 0A 04 04
					01 01 00 00 01 15 0A 00
					00 00 04 39 01 00 18 F4
					01 39 01 00 18 33 33 CC
					1C 02 19 10 0A 30 06 30
					06 0A 88 1F 40 00 40 00
					32 23 4B 50 37 3C 0C 0C
					00 00 14 14 00 03 00 03
					09 96 00 00 14 03 06 0F
					0A 00 4B FF 00 04 01 80
					04 1B 00 00 00 C8 00 F4
					01 BF 32 F4 01 00 C0 80
					00 10 0A 18 00 7D 01 04
					00 00 96 00 03 00 06 06
					07 07 00 C8 00 0D 0D 01
					04 02 25 00 10 00 00 00
					07 00 02 24 02 23 00 10
					00 03 00 07 00 02 26 02
					22 00 0F 00 06 00 04 00
					01 23 81 20 00 0E 00 09
					00 04 00 01 24 01 1E 00
					0E 00 0E 00 09 00 02 23
					81 1C 00 0D 00 13 00 09
					00 02 25 80 1B 00 0C 00
					18 00 05 00 01 23 00 19
					00 0B 00 1F 00 05 00 01
					26 00 00 00 00 00 00 00
					00 00 00 00 00 00 00 00
					09 0F 00 00 00 00 00 03
					03 03 03 03 03 03 03 03
					03 03 03 03 03 03 03 03
					03 03 03 03 03 0E 0D 0D
					0D 0D 0D 0D 0D 0D 0D 0D
					0D 0D 0D 0D 0E 0D 0D 0D
					0D 0D 0D 0D 0D 0D 0D 0D
					0D 0D 0D 0D 0B 02 02 01
					00 06 0B 0B 03 00 05 32
					00 06 00 A6 00 14 64 05
					02 02 02 02 04 04 04 04
					00 2F 05 05 00 3F 38 00
					05 02 18 21 02 06 1E 08
					A0 00 A0 00 1E 03 0C 0C
					0A 0A 04 00 00 00 00 00
					00 00 00 00 00 00 00 00
					00 FF FF FF FF FF FF FF
					FF BF 97 51 51 CD 0D 04
					83 10 10 10 10 05 20 1F
					1E 1D 1C 1B 1A 18 17 16
					15 14 13 12 11 FF FF FF
					FF FF FF FF 00 01 02 03
					04 05 06 07 08 09 0A 0B
					0C 0D 33 32 31 30 2F 2E
					2D 2C 2B 2A 29 28 27 FF
					FF FF FF FF 00 10 00 10
					00 10 00 10 80 80 80 80
					80 80 80 80 80 80 80 80
					80 80 80 80 80 80 80 80
					80 80 80 80 80 80 80 80
					80 80 80 80 80 80 80 80
					80 80 80 80 80 80 80 80
					80 80 80 80 80 80 80 80
					80 80 00 10 00 10 00 10
					00 10 00 00 21 22 FF FF
					0E 26 35 FF
				];
			};

			config_0key_3 {
				default_cfg   = <1>;
				pr_number     = <1558162>;
				sensor_id     = <0x0>;
				syn,pl-coords = <0 1620 0 2880>;
				config = [
					31 35 02 01 00 3F 03 1E
					05 0E 54 06 40 0B 23 43
					5A 41 00 00 00 00 0F 1B
					01 1E 05 CD 2C A9 01 50
					16 02 1B 01 17 C3 59 E1
					83 80 C4 C4 05 03 0A 1C
					80 0F 0A 32 00 01 01 07
					04 04 0A C0 19 64 26 26
					80 80 00 00 4D 1D 01 40
					40 32 50 00 00 00 00 4C
					04 6C 07 3C 32 00 00 00
					00 4C 04 6C 07 1E 05 1E
					04 0A 04 0A 00 0A 04 04
					00 00 00 00 01 15 0A 00
					00 00 06 39 01 00 18 00
					06 39 01 00 18 33 33 CC
					1C 02 19 10 0A 30 06 30
					06 0A 88 1F 40 00 40 00
					32 23 4B 50 37 3C 0C 0C
					00 00 14 14 10 03 10 03
					09 96 00 00 14 03 06 0F
					0A 00 4B FF 00 04 01 80
					04 1B 00 00 00 32 00 FF
					FF BE 4B 41 00 00 C0 80
					00 10 0A 18 00 79 05 0A
					00 00 90 01 03 00 06 06
					07 07 00 41 00 08 0C 01
					04 02 22 00 10 00 00 00
					07 00 02 24 02 21 00 10
					00 02 00 07 00 02 26 01
					20 00 0F 00 04 00 07 00
					02 27 01 1F 00 0F 00 06
					00 04 00 01 23 01 1E 00
					0F 00 08 00 04 00 01 24
					01 1D 00 0E 00 0A 00 04
					00 01 25 01 1C 00 0E 00
					0D 00 09 00 02 22 00 1B
					00 0D 00 10 00 09 00 02
					24 0F 0F 0F 0F 0F 0F 0F
					0F 0F 0F 0F 0F 0F 0F 0F
					09 0F 00 00 00 00 00 03
					03 03 03 03 03 03 03 03
					03 03 03 03 03 03 03 03
					03 03 03 03 03 0E 0D 0D
					0D 0D 0D 0D 0D 0D 0D 0D
					0D 0D 0D 0D 0E 0D 0D 0D
					0D 0D 0D 0D 0D 0D 0D 0D
					0D 0D 0D 0D 0B 03 03 02
					03 07 03 03 02 03 07 32
					00 06 00 A6 00 14 64 05
					00 00 03 03 00 00 03 03
					00 28 05 01 00 22 20 00
					05 02 16 01 00 06 08 08
					A0 00 A0 00 1E 03 0C 0C
					14 28 04 00 00 00 00 00
					00 00 00 00 00 00 00 00
					00 FF FF FF FF FF FF FF
					FF 51 51 51 51 CD 0D 04
					83 10 10 10 10 05 20 1F
					1E 1D 1C 1B 1A 18 17 16
					15 14 13 12 11 FF FF FF
					FF FF FF FF 00 01 02 03
					04 05 06 07 08 09 0A 0B
					0C 0D 33 32 31 30 2F 2E
					2D 2C 2B 2A 29 28 27 FF
					FF FF FF FF 00 10 00 10
					00 10 00 10 80 80 80 80
					80 80 80 80 80 80 80 80
					80 80 80 80 80 80 80 80
					80 80 80 80 80 80 80 80
					80 80 80 80 80 80 80 80
					80 80 80 80 80 80 80 80
					80 80 80 80 80 80 80 80
					80 80 00 10 00 10 00 10
					00 10 00 00 21 22 FF FF
					0E 26 35 FF
				];
			};

			config_pana_0key_2 {
				default_cfg   = <1>;
				pr_number     = <1558162>;
				sensor_id     = <0x1>;
				syn,pl-coords = <0 1620 0 2880>;
				config = [
					31 35 02 01 00 3F 03 1E
					05 0E 54 06 40 0B 23 43
					5A 41 00 00 00 00 0F 1B
					01 1E 05 CD 2C A9 01 50
					16 02 1B 01 17 C3 59 E1
					83 80 C4 C4 05 03 0A 1C
					80 0F 0A 32 00 01 01 07
					04 04 0A C0 19 64 26 26
					80 80 00 00 4D 1D 01 40
					40 32 50 00 00 00 00 4C
					04 6C 07 3C 32 00 00 00
					00 4C 04 6C 07 1E 05 1E
					04 0A 04 0A 00 0A 04 04
					00 00 00 00 01 15 0A 00
					00 00 06 39 01 00 18 00
					06 39 01 00 18 33 33 CC
					1C 02 19 10 0A 30 06 30
					06 0A 88 1F 40 00 40 00
					32 23 4B 50 37 3C 0C 0C
					00 00 14 14 10 03 10 03
					09 96 00 00 14 03 06 0F
					0A 00 4B FF 00 04 01 80
					04 1B 00 00 00 32 00 FF
					FF BE 4B 41 00 00 C0 80
					00 10 0A 18 00 79 05 0A
					00 00 90 01 03 00 06 06
					07 07 00 41 00 08 0C 01
					04 02 22 00 10 00 00 00
					07 00 02 24 02 21 00 10
					00 02 00 07 00 02 26 01
					20 00 0F 00 04 00 07 00
					02 27 01 1F 00 0F 00 06
					00 04 00 01 23 01 1E 00
					0F 00 08 00 04 00 01 24
					01 1D 00 0E 00 0A 00 04
					00 01 25 01 1C 00 0E 00
					0D 00 09 00 02 22 00 1B
					00 0D 00 10 00 09 00 02
					24 0F 0F 0F 0F 0F 0F 0F
					0F 0F 0F 0F 0F 0F 0F 0F
					09 0F 00 00 00 00 00 03
					03 03 03 03 03 03 03 03
					03 03 03 03 03 03 03 03
					03 03 03 03 03 0E 0D 0D
					0D 0D 0D 0D 0D 0D 0D 0D
					0D 0D 0D 0D 0E 0D 0D 0D
					0D 0D 0D 0D 0D 0D 0D 0D
					0D 0D 0D 0D 0B 03 03 02
					03 07 03 03 02 03 07 32
					00 06 00 A6 00 14 64 05
					00 00 03 03 00 00 03 03
					00 28 05 01 00 22 20 00
					05 02 16 01 00 06 08 08
					A0 00 A0 00 1E 03 0C 0C
					14 28 04 00 00 00 00 00
					00 00 00 00 00 00 00 00
					00 FF FF FF FF FF FF FF
					FF 51 51 51 51 CD 0D 04
					83 10 10 10 10 05 20 1F
					1E 1D 1C 1B 1A 18 17 16
					15 14 13 12 11 FF FF FF
					FF FF FF FF 00 01 02 03
					04 05 06 07 08 09 0A 0B
					0C 0D 33 32 31 30 2F 2E
					2D 2C 2B 2A 29 28 27 FF
					FF FF FF FF 00 10 00 10
					00 10 00 10 80 80 80 80
					80 80 80 80 80 80 80 80
					80 80 80 80 80 80 80 80
					80 80 80 80 80 80 80 80
					80 80 80 80 80 80 80 80
					80 80 80 80 80 80 80 80
					80 80 80 80 80 80 80 80
					80 80 00 10 00 10 00 10
					00 10 00 00 21 22 FF FF
					0E 26 35 FF
				];
			};

			config_yfo_0key_1 {
				default_cfg   = <1>;
				pr_number     = <1534450>;
				sensor_id     = <0x0>;
				syn,pl-coords = <0 1080 0 1920>;
				vkey_setting  = <1>;
				config = [
					31 35 F1 06 00 3F 03 1E
					05 0E 38 04 80 07 23 43
					5A 41 00 00 00 00 0F 1B
					01 1E 05 EF 32 E0 02 50
					19 01 1D 00 48 C9 05 E4
					83 80 C4 C4 05 03 12 1E
					5A 0F 0A 20 00 01 01 07
					04 04 0A C0 19 64 26 26
					80 80 00 00 1E 03 06 14
					28 10 40 10 04 04 3B 1C
					01 40 40 32 50 00 32 00
					00 00 00 4C 04 6C 07 3C
					32 00 00 00 00 4C 04 6C
					07 1E 05 00 00 00 01 15
					0A 00 00 00 06 39 01 00
					18 00 06 39 01 00 18 33
					33 CC 1C 02 19 10 0A 30
					06 30 06 0A 88 1F 40 00
					40 00 32 23 4B 50 37 3C
					0C 0C 00 00 14 14 10 03
					10 03 09 96 00 00 14 03
					06 0F 0A 00 4B FF 01 04
					01 80 04 1B 00 00 00 32
					00 00 00 BE 4B 41 00 00
					C0 80 00 10 0A 18 00 7D
					00 02 00 00 90 01 02 00
					06 06 07 07 00 41 00 08
					0C 01 04 80 15 00 11 00
					00 00 03 00 01 29 00 15
					00 10 00 03 00 07 00 02
					26 00 15 00 0F 00 06 00
					07 00 02 27 00 15 00 0F
					00 09 00 04 00 01 24 80
					15 00 0E 00 0C 00 04 00
					01 25 00 15 00 0E 00 0F
					00 09 00 02 23 80 15 00
					0D 00 12 00 09 00 02 24
					80 15 00 0D 00 15 00 09
					00 02 25 0F 0F 0F 0F 0F
					0F 0F 0F 0F 0F 0F 0F 0F
					0F 0F 00 0F 00 00 00 00
					00 03 03 03 03 03 03 03
					03 03 03 03 03 03 03 03
					03 03 03 03 03 03 03 0E
					0D 0D 0D 0D 0D 0D 0D 0D
					0D 0D 0D 0D 0D 0D 0E 0D
					0D 0D 0D 0D 0D 0D 0D 0D
					0D 0D 0D 0D 0D 0D 0B 01
					01 01 02 07 02 02 01 00
					05 32 00 05 00 A6 00 14
					64 05 00 00 02 02 06 06
					02 02 00 50 05 01 00 22
					20 00 05 02 16 00 00 00
					00 FF FF FF FF FF FF FF
					FF C2 C2 51 51 CD 0D 04
					83 10 10 10 10 05 20 1F
					1E 1D 1C 1B 1A 18 17 16
					15 14 13 12 11 FF FF FF
					FF FF FF FF 00 01 02 03
					04 05 06 07 08 09 0A 0B
					0C 0D 33 32 31 30 2F 2E
					2D 2C 2B 2A 29 28 27 FF
					FF FF FF FF 00 10 00 10
					00 10 00 10 80 80 80 80
					80 80 80 80 80 80 80 80
					80 80 80 80 80 80 80 80
					80 80 80 80 80 80 80 80
					80 80 80 80 80 80 80 80
					80 80 80 80 80 80 80 80
					80 80 80 80 80 80 80 80
					80 80 00 10 00 10 00 10
					00 10
				];
			};

			config_pana_0key_0 {
				default_cfg   = <1>;
				pr_number     = <1534450>;
				sensor_id     = <0x1>;
				syn,pl-coords = <0 1080 0 1920>;
				vkey_setting  = <1>;
				config = [
					31 35 F1 06 00 3F 03 1E
					05 0E 38 04 80 07 23 43
					5A 41 00 00 00 00 0F 1B
					01 1E 05 EF 32 E0 02 50
					19 01 1D 00 48 C9 05 E4
					83 80 C4 C4 05 03 12 1E
					5A 0F 0A 20 00 01 01 07
					04 04 0A C0 19 64 26 26
					80 80 00 00 1E 03 06 14
					28 10 40 10 04 04 3B 1C
					01 40 40 32 50 00 32 00
					00 00 00 4C 04 6C 07 3C
					32 00 00 00 00 4C 04 6C
					07 1E 05 00 00 00 01 15
					0A 00 00 00 06 39 01 00
					18 00 06 39 01 00 18 33
					33 CC 1C 02 19 10 0A 30
					06 30 06 0A 88 1F 40 00
					40 00 32 23 4B 50 37 3C
					0C 0C 00 00 14 14 10 03
					10 03 09 96 00 00 14 03
					06 0F 0A 00 4B FF 01 04
					01 80 04 1B 00 00 00 32
					00 00 00 BE 4B 41 00 00
					C0 80 00 10 0A 18 00 7D
					00 02 00 00 90 01 02 00
					06 06 07 07 00 41 00 08
					0C 01 04 80 15 00 11 00
					00 00 03 00 01 29 00 15
					00 10 00 03 00 07 00 02
					26 00 15 00 0F 00 06 00
					07 00 02 27 00 15 00 0F
					00 09 00 04 00 01 24 80
					15 00 0E 00 0C 00 04 00
					01 25 00 15 00 0E 00 0F
					00 09 00 02 23 80 15 00
					0D 00 12 00 09 00 02 24
					80 15 00 0D 00 15 00 09
					00 02 25 0F 0F 0F 0F 0F
					0F 0F 0F 0F 0F 0F 0F 0F
					0F 0F 00 0F 00 00 00 00
					00 03 03 03 03 03 03 03
					03 03 03 03 03 03 03 03
					03 03 03 03 03 03 03 0E
					0D 0D 0D 0D 0D 0D 0D 0D
					0D 0D 0D 0D 0D 0D 0E 0D
					0D 0D 0D 0D 0D 0D 0D 0D
					0D 0D 0D 0D 0D 0D 0B 01
					01 01 02 07 02 02 01 00
					05 32 00 05 00 A6 00 14
					64 05 00 00 02 02 06 06
					02 02 00 50 05 01 00 22
					20 00 05 02 16 00 00 00
					00 FF FF FF FF FF FF FF
					FF C2 C2 51 51 CD 0D 04
					83 10 10 10 10 05 20 1F
					1E 1D 1C 1B 1A 18 17 16
					15 14 13 12 11 FF FF FF
					FF FF FF FF 00 01 02 03
					04 05 06 07 08 09 0A 0B
					0C 0D 33 32 31 30 2F 2E
					2D 2C 2B 2A 29 28 27 FF
					FF FF FF FF 00 10 00 10
					00 10 00 10 80 80 80 80
					80 80 80 80 80 80 80 80
					80 80 80 80 80 80 80 80
					80 80 80 80 80 80 80 80
					80 80 80 80 80 80 80 80
					80 80 80 80 80 80 80 80
					80 80 80 80 80 80 80 80
					80 80 00 10 00 10 00 10
					00 10
				];
			};
		};

		synaptics_display_Sharp@20 {
			compatible               = "synaptics,3xxx";
			reg                      = <0x20>;
			interrupt-parent         = <&msmgpio>;
			interrupts               = <18 0x2>;
			synaptics,display-coords = <0 1080 0 1920>;
			synaptics,irq-gpio       = <&msmgpio 18 0x00>;
			synaptics,rst-gpio       = <&msmgpio 23 0x00>;
			synaptics,i2c-gpio       = <&msmgpio 94 0x00>;
			synaptics,i2c-gpio-ulj   = <&msmgpio 104 0x00>;
			synaptics,i2c_err_hlr    = <1>;
			tw_pin_mask              = <0x05>;
			hall_block_touch_time    = <1000>;
			report_type              = <1>;
			virtualkey0              = <&syn_vk>;
			virtualkey1              = <&syn_vk_1>;
			virtualkey2              = <&syn_vk_t6>;

			config_3528_0key_yfo_6 {
				default_cfg   = <1>;
				pr_number     = <1594356>;
				sensor_id     = <0x0>;
				syn,pl-coords = <0 1620 0 2880>;
				cover_setting = <0x0D 0x0D 0x1A 0x0A 0x82 0x82 0x06>;
				tp_stock_ui_check	 = <1>;
				config = [
					31 35 02 21 00 3F 03 14
					05 1D 54 06 40 0B 23 43
					5A 41 00 00 00 00 0F 1B
					01 1E 05 F5 28 1E 05 28
					10 03 12 02 CC C4 CC C4
					83 80 C4 C4 05 03 10 1E
					80 0F 0A 64 00 01 01 07
					04 04 0A C0 0A 64 26 26
					80 80 00 00 82 5F 48 64
					33 19 00 40 40 2D 50 00
					00 00 00 4C 04 6C 07 3C
					32 00 00 00 00 4C 04 6C
					07 1E 05 1E 04 0A 04 0A
					00 0A 04 04 01 01 00 00
					01 05 0A 01 00 00 06 39
					01 00 18 00 06 39 01 00
					18 33 33 CC 1C 02 19 10
					0A 64 06 64 06 C8 88 1F
					40 00 40 00 32 23 4B 50
					37 3C 0C 0C 00 00 14 14
					00 03 00 03 09 96 00 00
					14 03 06 0F 0A 00 4B FF
					00 0A C8 0A B4 64 B4 C8
					B4 C8 B4 C8 B4 C8 B4 C8
					00 05 DC 05 C8 32 C8 64
					C8 64 C8 64 C8 64 C8 64
					00 04 01 80 04 1B 00 00
					00 2C 01 FF FF BF 32 2C
					01 00 C0 80 00 10 0A 18
					00 7D 01 10 27 00 A0 00
					03 00 02 02 07 07 05 A0
					00 0C 0E 01 04 03 28 00
					10 00 00 00 07 00 02 25
					03 28 00 0F 00 02 00 07
					00 02 27 83 28 00 0F 00
					04 00 04 00 01 23 83 28
					00 0F 00 06 00 04 00 01
					24 83 28 00 0E 00 08 00
					04 00 01 25 83 28 00 0E
					00 0A 00 04 00 01 26 03
					28 00 0D 00 0D 00 09 00
					02 23 83 28 00 0D 00 10
					00 09 00 02 24 0E 0E 0E
					0E 0E 0E 0E 0F 0F 0F 0F
					0F 0F 0F 0F 00 00 00 00
					00 00 00 03 03 03 03 03
					03 03 03 03 03 03 03 03
					03 03 03 03 03 03 03 03
					03 0E 0D 0D 0D 0D 0D 0D
					0D 0D 0D 0D 0D 0D 0D 0D
					0E 0D 0D 0D 0D 0D 0D 0D
					0D 0D 0D 0D 0D 0D 0D 0D
					0B 02 02 01 00 07 0B 0B
					03 00 05 34 00 06 00 A6
					00 14 64 05 00 00 02 02
					04 04 04 04 03 1B 28 05
					00 00 16 12 00 05 02 14
					A1 02 06 1E 08 A0 00 A0
					00 1E 03 0C 0C 14 28 04
					00 00 00 00 00 00 00 00
					00 00 00 20 00 00 00 FF
					FF FF FF FF FF FF FF 51
					51 51 51 CD 0D 04 83 10
					10 10 10 05 20 1F 1E 1D
					1C 1B 1A 18 17 16 15 14
					13 12 11 FF FF FF FF FF
					FF FF 00 01 02 03 04 05
					06 07 08 09 0A 0B 0C 0D
					33 32 31 30 2F 2E 2D 2C
					2B 2A 29 28 27 FF FF FF
					FF FF 00 10 00 10 00 10
					00 10 80 80 80 80 80 80
					80 80 80 80 80 80 80 80
					80 80 80 80 80 80 80 80
					80 80 80 80 80 80 80 80
					80 80 80 80 80 80 80 9A
					9A 80 80 80 80 80 80 80
					80 80 80 80 80 80 80 80
					00 10 00 10 00 10 00 10
					00 00 21 22 FF FF 0E 26
					35 FF
				];
			};

			config_3528_0key_pana_6 {
				default_cfg   = <1>;
				pr_number     = <1594356>;
				sensor_id     = <0x1>;
				syn,pl-coords = <0 1620 0 2880>;
				cover_setting = <0x0D 0x0D 0x1A 0x0A 0x82 0x82 0x06>;
				tp_stock_ui_check	 = <1>;
				config = [
					31 35 02 21 00 3F 03 14
					05 1D 54 06 40 0B 23 43
					5A 41 00 00 00 00 0F 1B
					01 1E 05 F5 28 1E 05 28
					10 03 12 02 CC C4 CC C4
					83 80 C4 C4 05 03 10 1E
					80 0F 0A 64 00 01 01 07
					04 04 0A C0 0A 64 26 26
					80 80 00 00 82 5F 48 64
					33 19 00 40 40 2D 50 00
					00 00 00 4C 04 6C 07 3C
					32 00 00 00 00 4C 04 6C
					07 1E 05 1E 04 0A 04 0A
					00 0A 04 04 01 01 00 00
					01 05 0A 01 00 00 06 39
					01 00 18 00 06 39 01 00
					18 33 33 CC 1C 02 19 10
					0A 64 06 64 06 C8 88 1F
					40 00 40 00 32 23 4B 50
					37 3C 0C 0C 00 00 14 14
					00 03 00 03 09 96 00 00
					14 03 06 0F 0A 00 4B FF
					00 0A C8 0A B4 64 B4 C8
					B4 C8 B4 C8 B4 C8 B4 C8
					00 05 DC 05 C8 32 C8 64
					C8 64 C8 64 C8 64 C8 64
					00 04 01 80 04 1B 00 00
					00 2C 01 FF FF BF 32 2C
					01 00 C0 80 00 10 0A 18
					00 7D 01 10 27 00 A0 00
					03 00 02 02 07 07 05 A0
					00 0C 0E 01 04 03 28 00
					10 00 00 00 07 00 02 25
					03 28 00 0F 00 02 00 07
					00 02 27 83 28 00 0F 00
					04 00 04 00 01 23 83 28
					00 0F 00 06 00 04 00 01
					24 83 28 00 0E 00 08 00
					04 00 01 25 83 28 00 0E
					00 0A 00 04 00 01 26 03
					28 00 0D 00 0D 00 09 00
					02 23 83 28 00 0D 00 10
					00 09 00 02 24 0E 0E 0E
					0E 0E 0E 0E 0F 0F 0F 0F
					0F 0F 0F 0F 00 00 00 00
					00 00 00 03 03 03 03 03
					03 03 03 03 03 03 03 03
					03 03 03 03 03 03 03 03
					03 0E 0D 0D 0D 0D 0D 0D
					0D 0D 0D 0D 0D 0D 0D 0D
					0E 0D 0D 0D 0D 0D 0D 0D
					0D 0D 0D 0D 0D 0D 0D 0D
					0B 02 02 01 00 07 0B 0B
					03 00 05 34 00 06 00 A6
					00 14 64 05 00 00 02 02
					04 04 04 04 03 1B 28 05
					00 00 16 12 00 05 02 14
					A1 02 06 1E 08 A0 00 A0
					00 1E 03 0C 0C 14 28 04
					00 00 00 00 00 00 00 00
					00 00 00 20 00 00 00 FF
					FF FF FF FF FF FF FF 51
					51 51 51 CD 0D 04 83 10
					10 10 10 05 20 1F 1E 1D
					1C 1B 1A 18 17 16 15 14
					13 12 11 FF FF FF FF FF
					FF FF 00 01 02 03 04 05
					06 07 08 09 0A 0B 0C 0D
					33 32 31 30 2F 2E 2D 2C
					2B 2A 29 28 27 FF FF FF
					FF FF 00 10 00 10 00 10
					00 10 80 80 80 80 80 80
					80 80 80 80 80 80 80 80
					80 80 80 80 80 80 80 80
					80 80 80 80 80 80 80 80
					80 80 80 80 80 80 80 9A
					9A 80 80 80 80 80 80 80
					80 80 80 80 80 80 80 80
					00 10 00 10 00 10 00 10
					00 00 21 22 FF FF 0E 26
					35 FF
				];
			};

			config_3528_0key_yfo_5 {
				default_cfg   = <1>;
				pr_number     = <1594356>;
				sensor_id     = <0x0>;
				syn,pl-coords = <0 1620 0 2880>;
				cover_setting = <0x0D 0x0D 0x1A 0x0A 0x82 0x82 0x06>;
				config = [
					31 35 02 20 00 3F 03 14
					05 1D 54 06 40 0B 23 43
					5A 41 00 00 00 00 0F 1B
					01 1E 05 F5 28 1E 05 28
					10 03 12 02 CC C4 CC C4
					83 80 C4 C4 05 03 10 16
					80 0F 0A 64 00 01 01 07
					04 04 0A C0 0A 64 26 26
					80 80 00 00 82 5F 48 64
					2E 19 00 40 40 2D 50 00
					00 00 00 4C 04 6C 07 3C
					32 00 00 00 00 4C 04 6C
					07 1E 05 1E 04 0A 04 0A
					00 0A 04 04 01 01 00 00
					01 05 0A 01 00 00 06 39
					01 00 18 00 06 39 01 00
					18 33 33 CC 1C 02 19 10
					0A 64 06 64 06 C8 88 1F
					40 00 40 00 32 23 4B 50
					37 3C 0C 0C 00 00 14 14
					00 03 00 03 09 96 00 00
					14 03 06 0F 0A 00 4B FF
					00 0A C8 0A B4 64 B4 C8
					B4 C8 B4 C8 B4 C8 B4 C8
					00 05 DC 05 C8 32 C8 64
					C8 64 C8 64 C8 64 C8 64
					00 04 01 80 04 1B 00 00
					00 2C 01 FF FF BF 32 2C
					01 00 C0 80 00 10 0A 18
					00 7D 01 10 27 00 A0 00
					03 00 02 02 07 07 05 A0
					00 0C 0E 01 04 03 28 00
					10 00 00 00 07 00 02 25
					03 28 00 0F 00 02 00 07
					00 02 27 83 28 00 0F 00
					04 00 04 00 01 23 83 28
					00 0F 00 06 00 04 00 01
					24 83 28 00 0E 00 08 00
					04 00 01 25 83 28 00 0E
					00 0A 00 04 00 01 26 03
					28 00 0D 00 0D 00 09 00
					02 23 83 28 00 0D 00 10
					00 09 00 02 24 0E 0E 0E
					0E 0E 0E 0E 0F 0F 0F 0F
					0F 0F 0F 0F 00 00 00 00
					00 00 00 03 03 03 03 03
					03 03 03 03 03 03 03 03
					03 03 03 03 03 03 03 03
					03 0E 0D 0D 0D 0D 0D 0D
					0D 0D 0D 0D 0D 0D 0D 0D
					0E 0D 0D 0D 0D 0D 0D 0D
					0D 0D 0D 0D 0D 0D 0D 0D
					0B 02 02 01 00 07 0B 0B
					03 00 05 34 00 06 00 A6
					00 14 64 05 00 00 02 02
					04 04 04 04 03 1B 28 05
					00 00 16 12 00 05 02 14
					A1 02 06 1E 08 A0 00 A0
					00 1E 03 0C 0C 14 28 04
					00 00 00 00 00 00 00 00
					00 00 00 20 00 00 00 FF
					FF FF FF FF FF FF FF 51
					51 51 51 CD 0D 04 83 10
					10 10 10 05 20 1F 1E 1D
					1C 1B 1A 18 17 16 15 14
					13 12 11 FF FF FF FF FF
					FF FF 00 01 02 03 04 05
					06 07 08 09 0A 0B 0C 0D
					33 32 31 30 2F 2E 2D 2C
					2B 2A 29 28 27 FF FF FF
					FF FF 00 10 00 10 00 10
					00 10 80 80 80 80 80 80
					80 80 80 80 80 80 80 80
					80 80 80 80 80 80 80 80
					80 80 80 80 80 80 80 80
					80 80 80 80 80 80 80 9A
					9A 80 80 80 80 80 80 80
					80 80 80 80 80 80 80 80
					00 10 00 10 00 10 00 10
					00 00 21 22 FF FF 0E 26
					35 FF
				];
			};

			config_3528_0key_pana_5 {
				default_cfg   = <1>;
				pr_number     = <1594356>;
				sensor_id     = <0x1>;
				syn,pl-coords = <0 1620 0 2880>;
				cover_setting = <0x0D 0x0D 0x1A 0x0A 0x82 0x82 0x06>;
				config = [
					31 35 02 20 00 3F 03 14
					05 1D 54 06 40 0B 23 43
					5A 41 00 00 00 00 0F 1B
					01 1E 05 F5 28 1E 05 28
					10 03 12 02 CC C4 CC C4
					83 80 C4 C4 05 03 10 16
					80 0F 0A 64 00 01 01 07
					04 04 0A C0 0A 64 26 26
					80 80 00 00 82 5F 48 64
					2E 19 00 40 40 2D 50 00
					00 00 00 4C 04 6C 07 3C
					32 00 00 00 00 4C 04 6C
					07 1E 05 1E 04 0A 04 0A
					00 0A 04 04 01 01 00 00
					01 05 0A 01 00 00 06 39
					01 00 18 00 06 39 01 00
					18 33 33 CC 1C 02 19 10
					0A 64 06 64 06 C8 88 1F
					40 00 40 00 32 23 4B 50
					37 3C 0C 0C 00 00 14 14
					00 03 00 03 09 96 00 00
					14 03 06 0F 0A 00 4B FF
					00 0A C8 0A B4 64 B4 C8
					B4 C8 B4 C8 B4 C8 B4 C8
					00 05 DC 05 C8 32 C8 64
					C8 64 C8 64 C8 64 C8 64
					00 04 01 80 04 1B 00 00
					00 2C 01 FF FF BF 32 2C
					01 00 C0 80 00 10 0A 18
					00 7D 01 10 27 00 A0 00
					03 00 02 02 07 07 05 A0
					00 0C 0E 01 04 03 28 00
					10 00 00 00 07 00 02 25
					03 28 00 0F 00 02 00 07
					00 02 27 83 28 00 0F 00
					04 00 04 00 01 23 83 28
					00 0F 00 06 00 04 00 01
					24 83 28 00 0E 00 08 00
					04 00 01 25 83 28 00 0E
					00 0A 00 04 00 01 26 03
					28 00 0D 00 0D 00 09 00
					02 23 83 28 00 0D 00 10
					00 09 00 02 24 0E 0E 0E
					0E 0E 0E 0E 0F 0F 0F 0F
					0F 0F 0F 0F 00 00 00 00
					00 00 00 03 03 03 03 03
					03 03 03 03 03 03 03 03
					03 03 03 03 03 03 03 03
					03 0E 0D 0D 0D 0D 0D 0D
					0D 0D 0D 0D 0D 0D 0D 0D
					0E 0D 0D 0D 0D 0D 0D 0D
					0D 0D 0D 0D 0D 0D 0D 0D
					0B 02 02 01 00 07 0B 0B
					03 00 05 34 00 06 00 A6
					00 14 64 05 00 00 02 02
					04 04 04 04 03 1B 28 05
					00 00 16 12 00 05 02 14
					A1 02 06 1E 08 A0 00 A0
					00 1E 03 0C 0C 14 28 04
					00 00 00 00 00 00 00 00
					00 00 00 20 00 00 00 FF
					FF FF FF FF FF FF FF 51
					51 51 51 CD 0D 04 83 10
					10 10 10 05 20 1F 1E 1D
					1C 1B 1A 18 17 16 15 14
					13 12 11 FF FF FF FF FF
					FF FF 00 01 02 03 04 05
					06 07 08 09 0A 0B 0C 0D
					33 32 31 30 2F 2E 2D 2C
					2B 2A 29 28 27 FF FF FF
					FF FF 00 10 00 10 00 10
					00 10 80 80 80 80 80 80
					80 80 80 80 80 80 80 80
					80 80 80 80 80 80 80 80
					80 80 80 80 80 80 80 80
					80 80 80 80 80 80 80 9A
					9A 80 80 80 80 80 80 80
					80 80 80 80 80 80 80 80
					00 10 00 10 00 10 00 10
					00 00 21 22 FF FF 0E 26
					35 FF
				];
			};

			config_3528_0key_yfo_4 {
				default_cfg   = <1>;
				pr_number     = <1589401>;
				sensor_id     = <0x0>;
				syn,pl-coords = <0 1620 0 2880>;
				cover_setting = <0x0D 0x0D 0x1A 0x0A 0x82 0x82 0x06>;
				config = [
					31 35 02 14 00 3F 03 1E
					05 1D 54 06 40 0B 23 43
					5A 41 00 00 00 00 0F 1B
					01 1E 05 F5 28 1E 05 28
					10 03 12 02 CC C4 CC C4
					83 80 C4 C4 05 03 10 16
					80 0F 0A 64 00 01 01 07
					04 04 0A C0 0A 64 26 26
					80 80 00 00 82 5F 48 64
					2E 23 00 40 40 2D 50 00
					00 00 00 4C 04 6C 07 3C
					32 00 00 00 00 4C 04 6C
					07 1E 05 1E 04 0A 04 0A
					00 0A 04 04 01 01 00 00
					01 05 0A 01 00 00 06 39
					01 00 18 00 06 39 01 00
					18 33 33 CC 1C 02 19 10
					0A 64 06 64 06 C8 88 1F
					40 00 40 00 32 23 4B 50
					37 3C 0C 0C 00 00 14 14
					00 03 00 03 09 96 00 00
					14 03 06 0F 0A 00 4B FF
					00 0A C8 0A B4 64 B4 C8
					B4 C8 B4 C8 B4 C8 B4 C8
					00 05 DC 05 C8 32 C8 64
					C8 64 C8 64 C8 64 C8 64
					00 04 01 80 04 1B 00 00
					00 82 00 FF FF BF 32 2C
					01 00 C0 80 00 10 0A 18
					00 7D 01 04 00 00 A0 00
					03 00 02 02 07 07 05 A0
					00 0C 0E 02 04 00 1A 00
					10 00 00 00 07 00 02 25
					00 19 00 0F 00 02 00 07
					00 02 27 80 18 00 0F 00
					05 00 04 00 01 24 80 17
					00 0E 00 08 00 04 00 01
					25 00 16 00 0E 00 0B 00
					09 00 02 22 00 16 00 0D
					00 0E 00 09 00 02 24 80
					15 00 0D 00 11 00 09 00
					02 25 80 14 00 0C 00 15
					00 05 00 01 23 0E 0E 0E
					0E 0E 0E 0E 0F 0F 0F 0F
					0F 0F 0F 0F 00 00 00 00
					00 00 00 03 03 03 03 03
					03 03 03 03 03 03 03 03
					03 03 03 03 03 03 03 03
					03 0E 0D 0D 0D 0D 0D 0D
					0D 0D 0D 0D 0D 0D 0D 0D
					0E 0D 0D 0D 0D 0D 0D 0D
					0D 0D 0D 0D 0D 0D 0D 0D
					0B 02 02 01 00 07 0B 0B
					03 00 05 34 00 06 00 A6
					00 14 64 05 00 00 02 02
					04 04 04 04 03 1B 28 05
					00 00 16 12 00 05 02 16
					A1 02 06 1E 08 A0 00 A0
					00 1E 03 0C 0C 14 28 04
					00 00 00 00 00 00 00 00
					00 00 00 20 00 00 00 FF
					FF FF FF FF FF FF FF 51
					51 51 51 CD 0D 04 83 10
					10 10 10 05 20 1F 1E 1D
					1C 1B 1A 18 17 16 15 14
					13 12 11 FF FF FF FF FF
					FF FF 00 01 02 03 04 05
					06 07 08 09 0A 0B 0C 0D
					33 32 31 30 2F 2E 2D 2C
					2B 2A 29 28 27 FF FF FF
					FF FF 00 10 00 10 00 10
					00 10 80 80 80 80 80 80
					80 80 80 80 80 80 80 80
					80 80 80 80 80 80 80 80
					80 80 80 80 80 80 80 80
					80 80 80 80 80 80 80 80
					80 80 80 80 80 80 80 80
					80 80 80 80 80 80 80 80
					00 10 00 10 00 10 00 10
					00 00 21 22 FF FF 0E 26
					35 FF
				];
			};

			config_3528_0key_pana_4 {
				default_cfg   = <1>;
				pr_number     = <1589401>;
				sensor_id     = <0x1>;
				syn,pl-coords = <0 1620 0 2880>;
				cover_setting = <0x0D 0x0D 0x1A 0x0A 0x82 0x82 0x06>;
				config = [
					31 35 02 14 00 3F 03 1E
					05 1D 54 06 40 0B 23 43
					5A 41 00 00 00 00 0F 1B
					01 1E 05 F5 28 1E 05 28
					10 03 12 02 CC C4 CC C4
					83 80 C4 C4 05 03 10 16
					80 0F 0A 64 00 01 01 07
					04 04 0A C0 0A 64 26 26
					80 80 00 00 82 5F 48 64
					2E 23 00 40 40 2D 50 00
					00 00 00 4C 04 6C 07 3C
					32 00 00 00 00 4C 04 6C
					07 1E 05 1E 04 0A 04 0A
					00 0A 04 04 01 01 00 00
					01 05 0A 01 00 00 06 39
					01 00 18 00 06 39 01 00
					18 33 33 CC 1C 02 19 10
					0A 64 06 64 06 C8 88 1F
					40 00 40 00 32 23 4B 50
					37 3C 0C 0C 00 00 14 14
					00 03 00 03 09 96 00 00
					14 03 06 0F 0A 00 4B FF
					00 0A C8 0A B4 64 B4 C8
					B4 C8 B4 C8 B4 C8 B4 C8
					00 05 DC 05 C8 32 C8 64
					C8 64 C8 64 C8 64 C8 64
					00 04 01 80 04 1B 00 00
					00 82 00 FF FF BF 32 2C
					01 00 C0 80 00 10 0A 18
					00 7D 01 04 00 00 A0 00
					03 00 02 02 07 07 05 A0
					00 0C 0E 02 04 00 1A 00
					10 00 00 00 07 00 02 25
					00 19 00 0F 00 02 00 07
					00 02 27 80 18 00 0F 00
					05 00 04 00 01 24 80 17
					00 0E 00 08 00 04 00 01
					25 00 16 00 0E 00 0B 00
					09 00 02 22 00 16 00 0D
					00 0E 00 09 00 02 24 80
					15 00 0D 00 11 00 09 00
					02 25 80 14 00 0C 00 15
					00 05 00 01 23 0E 0E 0E
					0E 0E 0E 0E 0F 0F 0F 0F
					0F 0F 0F 0F 00 00 00 00
					00 00 00 03 03 03 03 03
					03 03 03 03 03 03 03 03
					03 03 03 03 03 03 03 03
					03 0E 0D 0D 0D 0D 0D 0D
					0D 0D 0D 0D 0D 0D 0D 0D
					0E 0D 0D 0D 0D 0D 0D 0D
					0D 0D 0D 0D 0D 0D 0D 0D
					0B 02 02 01 00 07 0B 0B
					03 00 05 34 00 06 00 A6
					00 14 64 05 00 00 02 02
					04 04 04 04 03 1B 28 05
					00 00 16 12 00 05 02 16
					A1 02 06 1E 08 A0 00 A0
					00 1E 03 0C 0C 14 28 04
					00 00 00 00 00 00 00 00
					00 00 00 20 00 00 00 FF
					FF FF FF FF FF FF FF 51
					51 51 51 CD 0D 04 83 10
					10 10 10 05 20 1F 1E 1D
					1C 1B 1A 18 17 16 15 14
					13 12 11 FF FF FF FF FF
					FF FF 00 01 02 03 04 05
					06 07 08 09 0A 0B 0C 0D
					33 32 31 30 2F 2E 2D 2C
					2B 2A 29 28 27 FF FF FF
					FF FF 00 10 00 10 00 10
					00 10 80 80 80 80 80 80
					80 80 80 80 80 80 80 80
					80 80 80 80 80 80 80 80
					80 80 80 80 80 80 80 80
					80 80 80 80 80 80 80 80
					80 80 80 80 80 80 80 80
					80 80 80 80 80 80 80 80
					00 10 00 10 00 10 00 10
					00 00 21 22 FF FF 0E 26
					35 FF
				];
			};

			config_3528_0key_yfo_3 {
				default_cfg   = <1>;
				pr_number     = <1584735>;
				sensor_id     = <0x0>;
				syn,pl-coords = <0 1620 0 2880>;
				config = [
					31 35 02 11 00 3F 03 1E
					05 1D 54 06 40 0B 23 43
					5A 41 00 00 00 00 0F 1B
					01 1E 05 F5 28 1E 05 28
					10 03 12 02 CC C4 CC C4
					83 80 C4 C4 05 03 1C 1E
					80 0F 0A 64 00 01 01 07
					04 04 0A C0 0A 64 26 26
					80 80 00 00 C0 53 5B 80
					2E 1A 00 40 40 2D 50 00
					00 00 00 4C 04 6C 07 3C
					32 00 00 00 00 4C 04 6C
					07 1E 05 1E 04 0A 04 0A
					00 0A 04 04 01 01 00 00
					01 05 0A 0A 00 00 06 39
					01 00 18 00 06 39 01 00
					18 33 33 CC 1C 02 19 10
					0A 64 06 64 06 C8 88 1F
					40 00 40 00 32 23 4B 50
					37 3C 0C 0C 00 00 14 14
					00 03 00 03 09 96 00 00
					14 03 06 0F 0A 00 4B FF
					FF 19 FF 19 FF 19 FF 19
					FF 19 FF 19 FF 19 FF 19
					FF 13 FF 13 FF 13 FF 13
					FF 13 FF 13 FF 13 FF 13
					00 04 01 80 04 1B 00 00
					00 64 00 F4 01 BF 28 F4
					01 00 C0 80 00 10 0A 18
					00 7D 01 03 00 00 64 00
					03 00 06 06 07 07 00 64
					00 0C 0E 01 04 00 1A 00
					10 00 00 00 07 00 02 25
					00 19 00 0F 00 02 00 07
					00 02 27 80 18 00 0F 00
					05 00 04 00 01 24 80 17
					00 0E 00 08 00 04 00 01
					25 00 16 00 0E 00 0B 00
					09 00 02 22 00 16 00 0D
					00 0E 00 09 00 02 24 80
					15 00 0D 00 11 00 09 00
					02 25 80 14 00 0C 00 15
					00 05 00 01 23 00 00 00
					00 00 00 00 00 00 00 00
					00 00 00 00 00 00 00 00
					00 00 00 03 03 03 03 03
					03 03 03 03 03 03 03 03
					03 03 03 03 03 03 03 03
					03 0E 0D 0D 0D 0D 0D 0D
					0D 0D 0D 0D 0D 0D 0D 0D
					0E 0D 0D 0D 0D 0D 0D 0D
					0D 0D 0D 0D 0D 0D 0D 0D
					0B 02 02 01 00 07 0B 0B
					03 00 05 34 00 06 00 A6
					00 14 64 05 00 00 02 02
					04 04 04 04 03 1B 28 05
					00 00 16 12 00 05 02 16
					A1 02 06 1E 08 A0 00 A0
					00 1E 03 0C 0C 14 28 04
					00 00 00 00 00 00 00 00
					00 00 00 20 00 00 00 FF
					FF FF FF FF FF FF FF 51
					51 51 51 CD 0D 04 83 10
					10 10 10 05 20 1F 1E 1D
					1C 1B 1A 18 17 16 15 14
					13 12 11 FF FF FF FF FF
					FF FF 00 01 02 03 04 05
					06 07 08 09 0A 0B 0C 0D
					33 32 31 30 2F 2E 2D 2C
					2B 2A 29 28 27 FF FF FF
					FF FF 00 10 00 10 00 10
					00 10 80 80 80 80 80 80
					80 80 80 80 80 80 80 80
					80 80 80 80 80 80 80 80
					80 80 80 80 80 80 80 80
					80 80 80 80 80 80 80 80
					80 80 80 80 80 80 80 80
					80 80 80 80 80 80 80 80
					00 10 00 10 00 10 00 10
					00 00 21 22 FF FF 0E 26
					35 FF
				];
			};

			config_3528_0key_pana_3 {
				default_cfg   = <1>;
				pr_number     = <1584735>;
				sensor_id     = <0x1>;
				syn,pl-coords = <0 1620 0 2880>;
				config = [
					31 35 02 11 00 3F 03 1E
					05 1D 54 06 40 0B 23 43
					5A 41 00 00 00 00 0F 1B
					01 1E 05 F5 28 1E 05 28
					10 03 12 02 CC C4 CC C4
					83 80 C4 C4 05 03 1C 1E
					80 0F 0A 64 00 01 01 07
					04 04 0A C0 0A 64 26 26
					80 80 00 00 C0 53 5B 80
					2E 1A 00 40 40 2D 50 00
					00 00 00 4C 04 6C 07 3C
					32 00 00 00 00 4C 04 6C
					07 1E 05 1E 04 0A 04 0A
					00 0A 04 04 01 01 00 00
					01 05 0A 0A 00 00 06 39
					01 00 18 00 06 39 01 00
					18 33 33 CC 1C 02 19 10
					0A 64 06 64 06 C8 88 1F
					40 00 40 00 32 23 4B 50
					37 3C 0C 0C 00 00 14 14
					00 03 00 03 09 96 00 00
					14 03 06 0F 0A 00 4B FF
					FF 19 FF 19 FF 19 FF 19
					FF 19 FF 19 FF 19 FF 19
					FF 13 FF 13 FF 13 FF 13
					FF 13 FF 13 FF 13 FF 13
					00 04 01 80 04 1B 00 00
					00 64 00 F4 01 BF 28 F4
					01 00 C0 80 00 10 0A 18
					00 7D 01 03 00 00 64 00
					03 00 06 06 07 07 00 64
					00 0C 0E 01 04 00 1A 00
					10 00 00 00 07 00 02 25
					00 19 00 0F 00 02 00 07
					00 02 27 80 18 00 0F 00
					05 00 04 00 01 24 80 17
					00 0E 00 08 00 04 00 01
					25 00 16 00 0E 00 0B 00
					09 00 02 22 00 16 00 0D
					00 0E 00 09 00 02 24 80
					15 00 0D 00 11 00 09 00
					02 25 80 14 00 0C 00 15
					00 05 00 01 23 00 00 00
					00 00 00 00 00 00 00 00
					00 00 00 00 00 00 00 00
					00 00 00 03 03 03 03 03
					03 03 03 03 03 03 03 03
					03 03 03 03 03 03 03 03
					03 0E 0D 0D 0D 0D 0D 0D
					0D 0D 0D 0D 0D 0D 0D 0D
					0E 0D 0D 0D 0D 0D 0D 0D
					0D 0D 0D 0D 0D 0D 0D 0D
					0B 02 02 01 00 07 0B 0B
					03 00 05 34 00 06 00 A6
					00 14 64 05 00 00 02 02
					04 04 04 04 03 1B 28 05
					00 00 16 12 00 05 02 16
					A1 02 06 1E 08 A0 00 A0
					00 1E 03 0C 0C 14 28 04
					00 00 00 00 00 00 00 00
					00 00 00 20 00 00 00 FF
					FF FF FF FF FF FF FF 51
					51 51 51 CD 0D 04 83 10
					10 10 10 05 20 1F 1E 1D
					1C 1B 1A 18 17 16 15 14
					13 12 11 FF FF FF FF FF
					FF FF 00 01 02 03 04 05
					06 07 08 09 0A 0B 0C 0D
					33 32 31 30 2F 2E 2D 2C
					2B 2A 29 28 27 FF FF FF
					FF FF 00 10 00 10 00 10
					00 10 80 80 80 80 80 80
					80 80 80 80 80 80 80 80
					80 80 80 80 80 80 80 80
					80 80 80 80 80 80 80 80
					80 80 80 80 80 80 80 80
					80 80 80 80 80 80 80 80
					80 80 80 80 80 80 80 80
					00 10 00 10 00 10 00 10
					00 00 21 22 FF FF 0E 26
					35 FF
				];
			};

			config_3528_0key_yfo_2 {
				default_cfg   = <1>;
				pr_number     = <1582731>;
				sensor_id     = <0x0>;
				syn,pl-coords = <0 1620 0 2880>;
				config = [
					31 35 02 09 00 3F 03 1E
					05 1D 54 06 40 0B 23 43
					5A 41 00 00 00 00 0F 1B
					01 1E 05 F5 28 1E 05 28
					10 03 12 02 CC C4 CC C4
					83 80 C4 C4 05 03 0C 12
					80 0F 0A 64 00 01 01 07
					04 04 0A C0 0A 64 26 26
					80 80 00 00 C0 53 5B 80
					26 0E 00 40 40 2D 50 00
					00 00 00 4C 04 6C 07 3C
					32 00 00 00 00 4C 04 6C
					07 1E 05 1E 04 0A 04 0A
					00 0A 04 04 01 01 00 00
					15 05 0A 0A 00 00 06 39
					01 00 18 00 06 39 01 00
					18 33 33 CC 1C 02 19 10
					0A 64 06 64 06 C8 88 1F
					40 00 40 00 32 23 4B 50
					37 3C 0C 0C 00 00 14 14
					00 03 00 03 09 96 00 00
					14 03 06 0F 0A 00 4B FF
					00 19 80 19 C0 80 C0 FF
					00 19 00 19 00 19 00 19
					00 13 C0 13 FF 80 FF FF
					FF FF FF FF FF FF FF FF
					00 04 01 80 04 1B 00 00
					00 64 00 F4 01 BF 28 F4
					01 00 C0 80 00 10 0A 18
					00 7D 01 03 00 00 96 00
					03 00 06 06 07 07 00 96
					00 0C 0E 01 04 00 1A 00
					10 00 00 00 07 00 02 25
					00 19 00 0F 00 02 00 07
					00 02 27 80 18 00 0F 00
					05 00 04 00 01 24 80 17
					00 0E 00 08 00 04 00 01
					25 00 16 00 0E 00 0B 00
					09 00 02 22 00 16 00 0D
					00 0E 00 09 00 02 24 80
					15 00 0D 00 11 00 09 00
					02 25 80 14 00 0C 00 15
					00 05 00 01 23 00 00 00
					00 00 00 00 00 00 00 00
					00 00 00 00 00 00 00 00
					00 00 00 03 03 03 03 03
					03 03 03 03 03 03 03 03
					03 03 03 03 03 03 03 03
					03 0E 0D 0D 0D 0D 0D 0D
					0D 0D 0D 0D 0D 0D 0D 0D
					0E 0D 0D 0D 0D 0D 0D 0D
					0D 0D 0D 0D 0D 0D 0D 0D
					0B 02 02 01 00 07 0B 0B
					03 00 05 34 00 06 00 A6
					00 14 64 05 00 00 02 02
					04 04 04 04 03 1B 28 05
					00 00 16 12 00 05 02 16
					A1 02 06 1E 08 A0 00 A0
					00 1E 03 0C 0C 14 28 04
					00 00 00 00 00 00 00 00
					00 00 00 20 00 00 00 FF
					FF FF FF FF FF FF FF 51
					51 51 51 CD 0D 04 83 10
					10 10 10 05 20 1F 1E 1D
					1C 1B 1A 18 17 16 15 14
					13 12 11 FF FF FF FF FF
					FF FF 00 01 02 03 04 05
					06 07 08 09 0A 0B 0C 0D
					33 32 31 30 2F 2E 2D 2C
					2B 2A 29 28 27 FF FF FF
					FF FF 00 10 00 10 00 10
					00 10 80 80 80 80 80 80
					80 80 80 80 80 80 80 80
					80 80 80 80 80 80 80 80
					80 80 80 80 80 80 80 80
					80 80 80 80 80 80 80 80
					80 80 80 80 80 80 80 80
					80 80 80 80 80 80 80 80
					00 10 00 10 00 10 00 10
					00 00 21 22 FF FF 0E 26
					35 FF
				];
			};

			config_3528_0key_pana_2 {
				default_cfg   = <1>;
				pr_number     = <1582731>;
				sensor_id     = <0x1>;
				syn,pl-coords = <0 1620 0 2880>;
				config = [
					31 35 02 09 00 3F 03 1E
					05 1D 54 06 40 0B 23 43
					5A 41 00 00 00 00 0F 1B
					01 1E 05 F5 28 1E 05 28
					10 03 12 02 CC C4 CC C4
					83 80 C4 C4 05 03 0C 12
					80 0F 0A 64 00 01 01 07
					04 04 0A C0 0A 64 26 26
					80 80 00 00 C0 53 5B 80
					26 0E 00 40 40 2D 50 00
					00 00 00 4C 04 6C 07 3C
					32 00 00 00 00 4C 04 6C
					07 1E 05 1E 04 0A 04 0A
					00 0A 04 04 01 01 00 00
					15 05 0A 0A 00 00 06 39
					01 00 18 00 06 39 01 00
					18 33 33 CC 1C 02 19 10
					0A 64 06 64 06 C8 88 1F
					40 00 40 00 32 23 4B 50
					37 3C 0C 0C 00 00 14 14
					00 03 00 03 09 96 00 00
					14 03 06 0F 0A 00 4B FF
					00 19 80 19 C0 80 C0 FF
					00 19 00 19 00 19 00 19
					00 13 C0 13 FF 80 FF FF
					FF FF FF FF FF FF FF FF
					00 04 01 80 04 1B 00 00
					00 64 00 F4 01 BF 28 F4
					01 00 C0 80 00 10 0A 18
					00 7D 01 03 00 00 96 00
					03 00 06 06 07 07 00 96
					00 0C 0E 01 04 00 1A 00
					10 00 00 00 07 00 02 25
					00 19 00 0F 00 02 00 07
					00 02 27 80 18 00 0F 00
					05 00 04 00 01 24 80 17
					00 0E 00 08 00 04 00 01
					25 00 16 00 0E 00 0B 00
					09 00 02 22 00 16 00 0D
					00 0E 00 09 00 02 24 80
					15 00 0D 00 11 00 09 00
					02 25 80 14 00 0C 00 15
					00 05 00 01 23 00 00 00
					00 00 00 00 00 00 00 00
					00 00 00 00 00 00 00 00
					00 00 00 03 03 03 03 03
					03 03 03 03 03 03 03 03
					03 03 03 03 03 03 03 03
					03 0E 0D 0D 0D 0D 0D 0D
					0D 0D 0D 0D 0D 0D 0D 0D
					0E 0D 0D 0D 0D 0D 0D 0D
					0D 0D 0D 0D 0D 0D 0D 0D
					0B 02 02 01 00 07 0B 0B
					03 00 05 34 00 06 00 A6
					00 14 64 05 00 00 02 02
					04 04 04 04 03 1B 28 05
					00 00 16 12 00 05 02 16
					A1 02 06 1E 08 A0 00 A0
					00 1E 03 0C 0C 14 28 04
					00 00 00 00 00 00 00 00
					00 00 00 20 00 00 00 FF
					FF FF FF FF FF FF FF 51
					51 51 51 CD 0D 04 83 10
					10 10 10 05 20 1F 1E 1D
					1C 1B 1A 18 17 16 15 14
					13 12 11 FF FF FF FF FF
					FF FF 00 01 02 03 04 05
					06 07 08 09 0A 0B 0C 0D
					33 32 31 30 2F 2E 2D 2C
					2B 2A 29 28 27 FF FF FF
					FF FF 00 10 00 10 00 10
					00 10 80 80 80 80 80 80
					80 80 80 80 80 80 80 80
					80 80 80 80 80 80 80 80
					80 80 80 80 80 80 80 80
					80 80 80 80 80 80 80 80
					80 80 80 80 80 80 80 80
					80 80 80 80 80 80 80 80
					00 10 00 10 00 10 00 10
					00 00 21 22 FF FF 0E 26
					35 FF
				];
			};

			config_3528_0key_yfo_1 {
				default_cfg   = <1>;
				pr_number     = <1564828>;
				sensor_id     = <0x0>;
				syn,pl-coords = <0 1620 0 2880>;
				config = [
					31 35 02 03 00 3F 03 05
					14 1D 54 06 40 0B 23 43
					5A 41 00 00 00 00 0F 1B
					01 1E 05 CD 2C A9 01 50
					16 02 1B 01 17 C3 59 E1
					83 80 C4 C4 05 03 0C 12
					80 0F 0A 64 00 01 01 07
					04 04 0A C0 0A 64 26 26
					80 80 00 00 4D 3B 01 40
					40 2D 50 00 00 00 00 4C
					04 6C 07 3C 32 00 00 00
					00 4C 04 6C 07 1E 05 1E
					04 0A 04 0A 00 0A 04 04
					01 01 00 00 01 15 0A 00
					00 00 04 39 01 00 18 F4
					01 39 01 00 18 33 33 CC
					1C 02 19 10 0A 30 06 30
					06 0A 88 1F 40 00 40 00
					32 23 4B 50 37 3C 0C 0C
					00 00 14 14 00 03 00 03
					09 96 00 00 14 03 06 0F
					0A 00 4B FF 00 04 01 80
					04 1B 00 00 00 C8 00 F4
					01 BF 32 F4 01 00 C0 80
					00 10 0A 18 00 7D 01 04
					00 00 96 00 03 00 06 06
					07 07 00 C8 00 0D 0D 01
					04 02 25 00 10 00 00 00
					07 00 02 24 02 23 00 10
					00 03 00 07 00 02 26 02
					22 00 0F 00 06 00 04 00
					01 23 81 20 00 0E 00 09
					00 04 00 01 24 01 1E 00
					0E 00 0E 00 09 00 02 23
					81 1C 00 0D 00 13 00 09
					00 02 25 80 1B 00 0C 00
					18 00 05 00 01 23 00 19
					00 0B 00 1F 00 05 00 01
					26 00 00 00 00 00 00 00
					00 00 00 00 00 00 00 00
					09 0F 00 00 00 00 00 03
					03 03 03 03 03 03 03 03
					03 03 03 03 03 03 03 03
					03 03 03 03 03 0E 0D 0D
					0D 0D 0D 0D 0D 0D 0D 0D
					0D 0D 0D 0D 0E 0D 0D 0D
					0D 0D 0D 0D 0D 0D 0D 0D
					0D 0D 0D 0D 0B 02 02 01
					00 06 0B 0B 03 00 05 32
					00 06 00 A6 00 14 64 05
					02 02 02 02 04 04 04 04
					00 2F 05 05 00 3F 38 00
					05 02 1A 21 02 06 1E 08
					A0 00 A0 00 1E 03 0C 0C
					0A 0A 04 00 00 00 00 00
					00 00 00 00 00 00 00 00
					00 FF FF FF FF FF FF FF
					FF BF 97 51 51 CD 0D 04
					83 10 10 10 10 05 20 1F
					1E 1D 1C 1B 1A 18 17 16
					15 14 13 12 11 FF FF FF
					FF FF FF FF 00 01 02 03
					04 05 06 07 08 09 0A 0B
					0C 0D 33 32 31 30 2F 2E
					2D 2C 2B 2A 29 28 27 FF
					FF FF FF FF 00 10 00 10
					00 10 00 10 80 80 80 80
					80 80 80 80 80 80 80 80
					80 80 80 80 80 80 80 80
					80 80 80 80 80 80 80 80
					80 80 80 80 80 80 80 80
					80 80 80 80 80 80 80 80
					80 80 80 80 80 80 80 80
					80 80 00 10 00 10 00 10
					00 10 00 00 21 22 FF FF
					0E 26 35 FF
				];
			};

			config_3528_0key_pana_1 {
				default_cfg   = <1>;
				pr_number     = <1564828>;
				sensor_id     = <0x1>;
				syn,pl-coords = <0 1620 0 2880>;
				config = [
					31 35 02 03 00 3F 03 05
					14 1D 54 06 40 0B 23 43
					5A 41 00 00 00 00 0F 1B
					01 1E 05 CD 2C A9 01 50
					16 02 1B 01 17 C3 59 E1
					83 80 C4 C4 05 03 0C 12
					80 0F 0A 64 00 01 01 07
					04 04 0A C0 0A 64 26 26
					80 80 00 00 4D 3B 01 40
					40 2D 50 00 00 00 00 4C
					04 6C 07 3C 32 00 00 00
					00 4C 04 6C 07 1E 05 1E
					04 0A 04 0A 00 0A 04 04
					01 01 00 00 01 15 0A 00
					00 00 04 39 01 00 18 F4
					01 39 01 00 18 33 33 CC
					1C 02 19 10 0A 30 06 30
					06 0A 88 1F 40 00 40 00
					32 23 4B 50 37 3C 0C 0C
					00 00 14 14 00 03 00 03
					09 96 00 00 14 03 06 0F
					0A 00 4B FF 00 04 01 80
					04 1B 00 00 00 C8 00 F4
					01 BF 32 F4 01 00 C0 80
					00 10 0A 18 00 7D 01 04
					00 00 96 00 03 00 06 06
					07 07 00 C8 00 0D 0D 01
					04 02 25 00 10 00 00 00
					07 00 02 24 02 23 00 10
					00 03 00 07 00 02 26 02
					22 00 0F 00 06 00 04 00
					01 23 81 20 00 0E 00 09
					00 04 00 01 24 01 1E 00
					0E 00 0E 00 09 00 02 23
					81 1C 00 0D 00 13 00 09
					00 02 25 80 1B 00 0C 00
					18 00 05 00 01 23 00 19
					00 0B 00 1F 00 05 00 01
					26 00 00 00 00 00 00 00
					00 00 00 00 00 00 00 00
					09 0F 00 00 00 00 00 03
					03 03 03 03 03 03 03 03
					03 03 03 03 03 03 03 03
					03 03 03 03 03 0E 0D 0D
					0D 0D 0D 0D 0D 0D 0D 0D
					0D 0D 0D 0D 0E 0D 0D 0D
					0D 0D 0D 0D 0D 0D 0D 0D
					0D 0D 0D 0D 0B 02 02 01
					00 06 0B 0B 03 00 05 32
					00 06 00 A6 00 14 64 05
					02 02 02 02 04 04 04 04
					00 2F 05 05 00 3F 38 00
					05 02 1A 21 02 06 1E 08
					A0 00 A0 00 1E 03 0C 0C
					0A 0A 04 00 00 00 00 00
					00 00 00 00 00 00 00 00
					00 FF FF FF FF FF FF FF
					FF BF 97 51 51 CD 0D 04
					83 10 10 10 10 05 20 1F
					1E 1D 1C 1B 1A 18 17 16
					15 14 13 12 11 FF FF FF
					FF FF FF FF 00 01 02 03
					04 05 06 07 08 09 0A 0B
					0C 0D 33 32 31 30 2F 2E
					2D 2C 2B 2A 29 28 27 FF
					FF FF FF FF 00 10 00 10
					00 10 00 10 80 80 80 80
					80 80 80 80 80 80 80 80
					80 80 80 80 80 80 80 80
					80 80 80 80 80 80 80 80
					80 80 80 80 80 80 80 80
					80 80 80 80 80 80 80 80
					80 80 80 80 80 80 80 80
					80 80 00 10 00 10 00 10
					00 10 00 00 21 22 FF FF
					0E 26 35 FF
				];
			};

			config_0key_3 {
				default_cfg   = <1>;
				pr_number     = <1558162>;
				sensor_id     = <0x0>;
				syn,pl-coords = <0 1620 0 2880>;
				config = [
					31 35 02 01 00 3F 03 1E
					05 0E 54 06 40 0B 23 43
					5A 41 00 00 00 00 0F 1B
					01 1E 05 CD 2C A9 01 50
					16 02 1B 01 17 C3 59 E1
					83 80 C4 C4 05 03 0A 1C
					80 0F 0A 32 00 01 01 07
					04 04 0A C0 19 64 26 26
					80 80 00 00 4D 1D 01 40
					40 32 50 00 00 00 00 4C
					04 6C 07 3C 32 00 00 00
					00 4C 04 6C 07 1E 05 1E
					04 0A 04 0A 00 0A 04 04
					00 00 00 00 01 15 0A 00
					00 00 06 39 01 00 18 00
					06 39 01 00 18 33 33 CC
					1C 02 19 10 0A 30 06 30
					06 0A 88 1F 40 00 40 00
					32 23 4B 50 37 3C 0C 0C
					00 00 14 14 10 03 10 03
					09 96 00 00 14 03 06 0F
					0A 00 4B FF 00 04 01 80
					04 1B 00 00 00 32 00 FF
					FF BE 4B 41 00 00 C0 80
					00 10 0A 18 00 79 05 0A
					00 00 90 01 03 00 06 06
					07 07 00 41 00 08 0C 01
					04 02 22 00 10 00 00 00
					07 00 02 24 02 21 00 10
					00 02 00 07 00 02 26 01
					20 00 0F 00 04 00 07 00
					02 27 01 1F 00 0F 00 06
					00 04 00 01 23 01 1E 00
					0F 00 08 00 04 00 01 24
					01 1D 00 0E 00 0A 00 04
					00 01 25 01 1C 00 0E 00
					0D 00 09 00 02 22 00 1B
					00 0D 00 10 00 09 00 02
					24 0F 0F 0F 0F 0F 0F 0F
					0F 0F 0F 0F 0F 0F 0F 0F
					09 0F 00 00 00 00 00 03
					03 03 03 03 03 03 03 03
					03 03 03 03 03 03 03 03
					03 03 03 03 03 0E 0D 0D
					0D 0D 0D 0D 0D 0D 0D 0D
					0D 0D 0D 0D 0E 0D 0D 0D
					0D 0D 0D 0D 0D 0D 0D 0D
					0D 0D 0D 0D 0B 03 03 02
					03 07 03 03 02 03 07 32
					00 06 00 A6 00 14 64 05
					00 00 03 03 00 00 03 03
					00 28 05 01 00 22 20 00
					05 02 16 01 00 06 08 08
					A0 00 A0 00 1E 03 0C 0C
					14 28 04 00 00 00 00 00
					00 00 00 00 00 00 00 00
					00 FF FF FF FF FF FF FF
					FF 51 51 51 51 CD 0D 04
					83 10 10 10 10 05 20 1F
					1E 1D 1C 1B 1A 18 17 16
					15 14 13 12 11 FF FF FF
					FF FF FF FF 00 01 02 03
					04 05 06 07 08 09 0A 0B
					0C 0D 33 32 31 30 2F 2E
					2D 2C 2B 2A 29 28 27 FF
					FF FF FF FF 00 10 00 10
					00 10 00 10 80 80 80 80
					80 80 80 80 80 80 80 80
					80 80 80 80 80 80 80 80
					80 80 80 80 80 80 80 80
					80 80 80 80 80 80 80 80
					80 80 80 80 80 80 80 80
					80 80 80 80 80 80 80 80
					80 80 00 10 00 10 00 10
					00 10 00 00 21 22 FF FF
					0E 26 35 FF
				];
			};

			config_pana_0key_2 {
				default_cfg   = <1>;
				pr_number     = <1558162>;
				sensor_id     = <0x1>;
				syn,pl-coords = <0 1620 0 2880>;
				config = [
					31 35 02 01 00 3F 03 1E
					05 0E 54 06 40 0B 23 43
					5A 41 00 00 00 00 0F 1B
					01 1E 05 CD 2C A9 01 50
					16 02 1B 01 17 C3 59 E1
					83 80 C4 C4 05 03 0A 1C
					80 0F 0A 32 00 01 01 07
					04 04 0A C0 19 64 26 26
					80 80 00 00 4D 1D 01 40
					40 32 50 00 00 00 00 4C
					04 6C 07 3C 32 00 00 00
					00 4C 04 6C 07 1E 05 1E
					04 0A 04 0A 00 0A 04 04
					00 00 00 00 01 15 0A 00
					00 00 06 39 01 00 18 00
					06 39 01 00 18 33 33 CC
					1C 02 19 10 0A 30 06 30
					06 0A 88 1F 40 00 40 00
					32 23 4B 50 37 3C 0C 0C
					00 00 14 14 10 03 10 03
					09 96 00 00 14 03 06 0F
					0A 00 4B FF 00 04 01 80
					04 1B 00 00 00 32 00 FF
					FF BE 4B 41 00 00 C0 80
					00 10 0A 18 00 79 05 0A
					00 00 90 01 03 00 06 06
					07 07 00 41 00 08 0C 01
					04 02 22 00 10 00 00 00
					07 00 02 24 02 21 00 10
					00 02 00 07 00 02 26 01
					20 00 0F 00 04 00 07 00
					02 27 01 1F 00 0F 00 06
					00 04 00 01 23 01 1E 00
					0F 00 08 00 04 00 01 24
					01 1D 00 0E 00 0A 00 04
					00 01 25 01 1C 00 0E 00
					0D 00 09 00 02 22 00 1B
					00 0D 00 10 00 09 00 02
					24 0F 0F 0F 0F 0F 0F 0F
					0F 0F 0F 0F 0F 0F 0F 0F
					09 0F 00 00 00 00 00 03
					03 03 03 03 03 03 03 03
					03 03 03 03 03 03 03 03
					03 03 03 03 03 0E 0D 0D
					0D 0D 0D 0D 0D 0D 0D 0D
					0D 0D 0D 0D 0E 0D 0D 0D
					0D 0D 0D 0D 0D 0D 0D 0D
					0D 0D 0D 0D 0B 03 03 02
					03 07 03 03 02 03 07 32
					00 06 00 A6 00 14 64 05
					00 00 03 03 00 00 03 03
					00 28 05 01 00 22 20 00
					05 02 16 01 00 06 08 08
					A0 00 A0 00 1E 03 0C 0C
					14 28 04 00 00 00 00 00
					00 00 00 00 00 00 00 00
					00 FF FF FF FF FF FF FF
					FF 51 51 51 51 CD 0D 04
					83 10 10 10 10 05 20 1F
					1E 1D 1C 1B 1A 18 17 16
					15 14 13 12 11 FF FF FF
					FF FF FF FF 00 01 02 03
					04 05 06 07 08 09 0A 0B
					0C 0D 33 32 31 30 2F 2E
					2D 2C 2B 2A 29 28 27 FF
					FF FF FF FF 00 10 00 10
					00 10 00 10 80 80 80 80
					80 80 80 80 80 80 80 80
					80 80 80 80 80 80 80 80
					80 80 80 80 80 80 80 80
					80 80 80 80 80 80 80 80
					80 80 80 80 80 80 80 80
					80 80 80 80 80 80 80 80
					80 80 00 10 00 10 00 10
					00 10 00 00 21 22 FF FF
					0E 26 35 FF
				];
			};

			config_yfo_0key_1 {
				default_cfg   = <1>;
				pr_number     = <1534450>;
				sensor_id     = <0x0>;
				syn,pl-coords = <0 1080 0 1920>;
				vkey_setting  = <1>;
				config = [
					31 35 F1 06 00 3F 03 1E
					05 0E 38 04 80 07 23 43
					5A 41 00 00 00 00 0F 1B
					01 1E 05 EF 32 E0 02 50
					19 01 1D 00 48 C9 05 E4
					83 80 C4 C4 05 03 12 1E
					5A 0F 0A 20 00 01 01 07
					04 04 0A C0 19 64 26 26
					80 80 00 00 1E 03 06 14
					28 10 40 10 04 04 3B 1C
					01 40 40 32 50 00 32 00
					00 00 00 4C 04 6C 07 3C
					32 00 00 00 00 4C 04 6C
					07 1E 05 00 00 00 01 15
					0A 00 00 00 06 39 01 00
					18 00 06 39 01 00 18 33
					33 CC 1C 02 19 10 0A 30
					06 30 06 0A 88 1F 40 00
					40 00 32 23 4B 50 37 3C
					0C 0C 00 00 14 14 10 03
					10 03 09 96 00 00 14 03
					06 0F 0A 00 4B FF 01 04
					01 80 04 1B 00 00 00 32
					00 00 00 BE 4B 41 00 00
					C0 80 00 10 0A 18 00 7D
					00 02 00 00 90 01 02 00
					06 06 07 07 00 41 00 08
					0C 01 04 80 15 00 11 00
					00 00 03 00 01 29 00 15
					00 10 00 03 00 07 00 02
					26 00 15 00 0F 00 06 00
					07 00 02 27 00 15 00 0F
					00 09 00 04 00 01 24 80
					15 00 0E 00 0C 00 04 00
					01 25 00 15 00 0E 00 0F
					00 09 00 02 23 80 15 00
					0D 00 12 00 09 00 02 24
					80 15 00 0D 00 15 00 09
					00 02 25 0F 0F 0F 0F 0F
					0F 0F 0F 0F 0F 0F 0F 0F
					0F 0F 00 0F 00 00 00 00
					00 03 03 03 03 03 03 03
					03 03 03 03 03 03 03 03
					03 03 03 03 03 03 03 0E
					0D 0D 0D 0D 0D 0D 0D 0D
					0D 0D 0D 0D 0D 0D 0E 0D
					0D 0D 0D 0D 0D 0D 0D 0D
					0D 0D 0D 0D 0D 0D 0B 01
					01 01 02 07 02 02 01 00
					05 32 00 05 00 A6 00 14
					64 05 00 00 02 02 06 06
					02 02 00 50 05 01 00 22
					20 00 05 02 16 00 00 00
					00 FF FF FF FF FF FF FF
					FF C2 C2 51 51 CD 0D 04
					83 10 10 10 10 05 20 1F
					1E 1D 1C 1B 1A 18 17 16
					15 14 13 12 11 FF FF FF
					FF FF FF FF 00 01 02 03
					04 05 06 07 08 09 0A 0B
					0C 0D 33 32 31 30 2F 2E
					2D 2C 2B 2A 29 28 27 FF
					FF FF FF FF 00 10 00 10
					00 10 00 10 80 80 80 80
					80 80 80 80 80 80 80 80
					80 80 80 80 80 80 80 80
					80 80 80 80 80 80 80 80
					80 80 80 80 80 80 80 80
					80 80 80 80 80 80 80 80
					80 80 80 80 80 80 80 80
					80 80 00 10 00 10 00 10
					00 10
				];
			};

			config_pana_0key_0 {
				default_cfg   = <1>;
				pr_number     = <1534450>;
				sensor_id     = <0x1>;
				syn,pl-coords = <0 1080 0 1920>;
				vkey_setting  = <1>;
				config = [
					31 35 F1 06 00 3F 03 1E
					05 0E 38 04 80 07 23 43
					5A 41 00 00 00 00 0F 1B
					01 1E 05 EF 32 E0 02 50
					19 01 1D 00 48 C9 05 E4
					83 80 C4 C4 05 03 12 1E
					5A 0F 0A 20 00 01 01 07
					04 04 0A C0 19 64 26 26
					80 80 00 00 1E 03 06 14
					28 10 40 10 04 04 3B 1C
					01 40 40 32 50 00 32 00
					00 00 00 4C 04 6C 07 3C
					32 00 00 00 00 4C 04 6C
					07 1E 05 00 00 00 01 15
					0A 00 00 00 06 39 01 00
					18 00 06 39 01 00 18 33
					33 CC 1C 02 19 10 0A 30
					06 30 06 0A 88 1F 40 00
					40 00 32 23 4B 50 37 3C
					0C 0C 00 00 14 14 10 03
					10 03 09 96 00 00 14 03
					06 0F 0A 00 4B FF 01 04
					01 80 04 1B 00 00 00 32
					00 00 00 BE 4B 41 00 00
					C0 80 00 10 0A 18 00 7D
					00 02 00 00 90 01 02 00
					06 06 07 07 00 41 00 08
					0C 01 04 80 15 00 11 00
					00 00 03 00 01 29 00 15
					00 10 00 03 00 07 00 02
					26 00 15 00 0F 00 06 00
					07 00 02 27 00 15 00 0F
					00 09 00 04 00 01 24 80
					15 00 0E 00 0C 00 04 00
					01 25 00 15 00 0E 00 0F
					00 09 00 02 23 80 15 00
					0D 00 12 00 09 00 02 24
					80 15 00 0D 00 15 00 09
					00 02 25 0F 0F 0F 0F 0F
					0F 0F 0F 0F 0F 0F 0F 0F
					0F 0F 00 0F 00 00 00 00
					00 03 03 03 03 03 03 03
					03 03 03 03 03 03 03 03
					03 03 03 03 03 03 03 0E
					0D 0D 0D 0D 0D 0D 0D 0D
					0D 0D 0D 0D 0D 0D 0E 0D
					0D 0D 0D 0D 0D 0D 0D 0D
					0D 0D 0D 0D 0D 0D 0B 01
					01 01 02 07 02 02 01 00
					05 32 00 05 00 A6 00 14
					64 05 00 00 02 02 06 06
					02 02 00 50 05 01 00 22
					20 00 05 02 16 00 00 00
					00 FF FF FF FF FF FF FF
					FF C2 C2 51 51 CD 0D 04
					83 10 10 10 10 05 20 1F
					1E 1D 1C 1B 1A 18 17 16
					15 14 13 12 11 FF FF FF
					FF FF FF FF 00 01 02 03
					04 05 06 07 08 09 0A 0B
					0C 0D 33 32 31 30 2F 2E
					2D 2C 2B 2A 29 28 27 FF
					FF FF FF FF 00 10 00 10
					00 10 00 10 80 80 80 80
					80 80 80 80 80 80 80 80
					80 80 80 80 80 80 80 80
					80 80 80 80 80 80 80 80
					80 80 80 80 80 80 80 80
					80 80 80 80 80 80 80 80
					80 80 80 80 80 80 80 80
					80 80 00 10 00 10 00 10
					00 10
				];
			};
		};
	};
};

